AUTOSAR XML (schema 4-0-1)
standard types defined: Boolean, Double, Double_dataConstr, Double_with_NaN, Float, Float_dataConstr, Float_with_NaN, SInt16, SInt16_dataConstr, SInt32, SInt32_dataConstr, SInt8, SInt8_dataConstr, UInt16, UInt16_dataConstr, UInt32, UInt32_dataConstr, UInt8, UInt8_dataConstr, float32, float64, sint16, sint32, sint8, uint16, uint32, uint8, boolean
package /AUTOSAR/DataTypes
  impl type ACC_ACCEPBrequest_datatype: compu {identical}, implementation-data-type=boolean
  impl type ACC_ACCMode_datatype: compu {identical}, range raw 0..255, implementation-data-type=uint8
  impl type ACC_ACCTargetAcceleration_datatype: compu {texttable; unit m/s2}, range raw 0..255, implementation-data-type=uint8
  impl type ACC_ACCTargetDirection_datatype: compu {identical}, range raw 0..255, implementation-data-type=uint8
  impl type ACC_ACCTargetID_datatype: compu {texttable}, range raw 0..255, implementation-data-type=uint8
  impl type ACC_ACCTargetLatRange_datatype: compu {texttable; unit m}, range raw 0..65535, implementation-data-type=uint16
  impl type ACC_ACCTargetLngRange_datatype: compu {texttable; unit m}, range raw 0..65535, implementation-data-type=uint16
  impl type ACC_ACCTargetRelSpd_datatype: compu {texttable; unit km/h}, range raw 0..65535, implementation-data-type=uint16
  impl type ACC_ACCTargetType_datatype: compu {identical}, range raw 0..255, implementation-data-type=uint8
  impl type ACC_AWBlevel_datatype: compu {identical}, range raw 0..255, implementation-data-type=uint8
  impl type ACC_AccTrqReqActive_datatype: compu {identical}, implementation-data-type=boolean
  impl type ACC_AccTrqReq_datatype: compu {texttable; unit Nm}, range raw 0..65535, implementation-data-type=uint16
  impl type ACC_CDDActive_datatype: compu {identical}, implementation-data-type=boolean
  impl type ACC_CRCCheck_1BA_0_datatype: compu {texttable}, range raw 0..255, implementation-data-type=uint8
  impl type ACC_CRCCheck_1BA_1_datatype: compu {texttable}, range raw 0..255, implementation-data-type=uint8
  impl type ACC_CRCCheck_24E_datatype: compu {texttable}, range raw 0..255, implementation-data-type=uint8
  impl type ACC_CRCCheck_25E_datatype: compu {texttable}, range raw 0..255, implementation-data-type=uint8
  impl type ACC_CRCCheck_307_datatype: compu {texttable}, range raw 0..65535, implementation-data-type=uint16
  impl type ACC_CRCCheck_30A_datatype: compu {texttable}, range raw 0..255, implementation-data-type=uint8
  impl type ACC_CRCCheck_30D_datatype: compu {texttable}, range raw 0..255, implementation-data-type=uint8
  impl type ACC_CRCCheck_31A_datatype: compu {texttable}, range raw 0..65535, implementation-data-type=uint16
  impl type ACC_CRCCheck_322_datatype: compu {texttable}, range raw 0..255, implementation-data-type=uint8
  impl type ACC_CRCCheck_344_datatype: compu {texttable}, range raw 0..255, implementation-data-type=uint8
  impl type ACC_CRCCheck_35E_datatype: compu {texttable}, range raw 0..255, implementation-data-type=uint8
  impl type ACC_CRCCheck_35F_datatype: compu {texttable}, range raw 0..255, implementation-data-type=uint8
  impl type ACC_CRCCheck_367_datatype: compu {texttable}, range raw 0..255, implementation-data-type=uint8
  impl type ACC_CRCCheck_36D_datatype: compu {texttable}, range raw 0..255, implementation-data-type=uint8
  impl type ACC_CRCCheck_3E4_datatype: compu {texttable}, range raw 0..255, implementation-data-type=uint8
  impl type ACC_DecToStop_datatype: compu {identical}, implementation-data-type=boolean
  impl type ACC_DistanceLevel_datatype: compu {identical}, range raw 0..255, implementation-data-type=uint8
  impl type ACC_Driveoff_Request_datatype: compu {identical}, implementation-data-type=boolean
  impl type ACC_DriverHandsOffStatus_datatype: compu {identical}, range raw 0..255, implementation-data-type=uint8
  impl type ACC_EmergencyLightingRequest_datatype: compu {identical}, range raw 0..255, implementation-data-type=uint8
  impl type ACC_HandsOnReq_datatype: compu {identical}, range raw 0..255, implementation-data-type=uint8
  impl type ACC_HostLaneLeftStatus_datatype: compu {identical}, range raw 0..255, implementation-data-type=uint8
  impl type ACC_HostLaneRightStatus_datatype: compu {identical}, range raw 0..255, implementation-data-type=uint8
  impl type ACC_IACCHWAMode_datatype: compu {identical}, range raw 0..255, implementation-data-type=uint8
  impl type ACC_IACCHWATextInfoForDriver_datatype: compu {identical}, range raw 0..255, implementation-data-type=uint8
  impl type ACC_LLaneDistanceFusion_datatype: compu {texttable; unit m}, range raw 0..255, implementation-data-type=uint8
  impl type ACC_LatAngReqActive_datatype: compu {identical}, implementation-data-type=boolean
  impl type ACC_LatAngReq_datatype: compu {texttable; unit degree}, range raw 0..65535, implementation-data-type=uint16
  impl type ACC_LatTakeoverReq_datatype: compu {identical}, range raw 0..255, implementation-data-type=uint8
  impl type ACC_LngTakeOverReq_datatype: compu {identical}, range raw 0..255, implementation-data-type=uint8
  impl type ACC_MotorTorqueMaxLimitRequest_datatype: compu {texttable; unit Nm}, range raw 0..65535, implementation-data-type=uint16
  impl type ACC_MotorTorqueMinLimitRequest_datatype: compu {texttable; unit Nm}, range raw 0..65535, implementation-data-type=uint16
  impl type ACC_ObjValid_datatype: compu {identical}, implementation-data-type=boolean
  impl type ACC_RLaneDistanceFusion_datatype: compu {texttable; unit m}, range raw 0..255, implementation-data-type=uint8
  impl type ACC_RollingCounter_1BA_0_datatype: compu {texttable}, range raw 0..255, implementation-data-type=uint8
  impl type ACC_RollingCounter_1BA_1_datatype: compu {texttable}, range raw 0..255, implementation-data-type=uint8
  impl type ACC_RollingCounter_24E_datatype: compu {texttable}, range raw 0..255, implementation-data-type=uint8
  impl type ACC_RollingCounter_25E_datatype: compu {texttable}, range raw 0..255, implementation-data-type=uint8
  impl type ACC_RollingCounter_307_datatype: compu {texttable}, range raw 0..255, implementation-data-type=uint8
  impl type ACC_RollingCounter_30A_datatype: compu {texttable}, range raw 0..255, implementation-data-type=uint8
  impl type ACC_RollingCounter_30D_datatype: compu {texttable}, range raw 0..255, implementation-data-type=uint8
  impl type ACC_RollingCounter_31A_datatype: compu {texttable}, range raw 0..255, implementation-data-type=uint8
  impl type ACC_RollingCounter_322_datatype: compu {texttable}, range raw 0..255, implementation-data-type=uint8
  impl type ACC_RollingCounter_344_datatype: compu {texttable}, range raw 0..255, implementation-data-type=uint8
  impl type ACC_RollingCounter_35E_datatype: compu {texttable}, range raw 0..255, implementation-data-type=uint8
  impl type ACC_RollingCounter_35F_datatype: compu {texttable}, range raw 0..255, implementation-data-type=uint8
  impl type ACC_RollingCounter_367_datatype: compu {texttable}, range raw 0..255, implementation-data-type=uint8
  impl type ACC_RollingCounter_36D_datatype: compu {texttable}, range raw 0..255, implementation-data-type=uint8
  impl type ACC_RollingCounter_3E4_datatype: compu {texttable}, range raw 0..255, implementation-data-type=uint8
  impl type ACC_SaftyBeltVibrationReq_datatype: compu {identical}, implementation-data-type=boolean
  impl type ACC_SaftyBelt_Tightened_datatype: compu {identical}, range raw 0..255, implementation-data-type=uint8
  impl type ACC_SetSpeed_datatype: compu {texttable; unit Km/h}, range raw 0..255, implementation-data-type=uint8
  impl type ACC_TargetBasedLateralControl_datatype: compu {identical}, range raw 0..255, implementation-data-type=uint8
  impl type ACC_TextInfoForDriver_datatype: compu {identical}, range raw 0..255, implementation-data-type=uint8
  impl type ACC_TimeGapSet_datatype: compu {identical}, range raw 0..255, implementation-data-type=uint8
  impl type ACC_Voiceinfo_datatype: compu {identical}, range raw 0..255, implementation-data-type=uint8
  impl type ADS_Authernticator_1BA_datatype: category=ARRAY, compu {texttable}
    element ADS_Authernticator_1BA_datatype: array-size=8, array-size-semantics=FIXED-SIZE, implementation-data-type=uint8
  impl type ADS_Authernticator_244_datatype: category=ARRAY, compu {texttable}
    element ADS_Authernticator_244_datatype: array-size=8, array-size-semantics=FIXED-SIZE, implementation-data-type=uint8
  impl type ADS_CRCCheck_244_datatype: compu {texttable}, range raw 0..65535, implementation-data-type=uint16
  impl type ADS_CRCCheck_312_datatype: compu {texttable}, range raw 0..65535, implementation-data-type=uint16
  impl type ADS_MesssageCounter_1BA_datatype: compu {texttable}, range raw 0..255, implementation-data-type=uint8
  impl type ADS_MesssageCounter_244_datatype: compu {texttable}, range raw 0..255, implementation-data-type=uint8
  impl type ADS_ResetFlag_1BA_datatype: compu {texttable}, range raw 0..255, implementation-data-type=uint8
  impl type ADS_ResetFlag_244_datatype: compu {texttable}, range raw 0..255, implementation-data-type=uint8
  impl type ADS_RollingCounter_244_datatype: compu {texttable}, range raw 0..255, implementation-data-type=uint8
  impl type ADS_RollingCounter_312_datatype: compu {texttable}, range raw 0..255, implementation-data-type=uint8
  impl type BCM_CRCCheck_28B_datatype: compu {texttable}, range raw 0..255, implementation-data-type=uint8
  impl type BCM_RollingCounter_28B_datatype: compu {texttable}, range raw 0..255, implementation-data-type=uint8
  impl type BCM_TurnLightSwitchSts_datatype: compu {identical}, range raw 0..255, implementation-data-type=uint8
  impl type BcmAutHeadLiSts_datatype: compu {identical}, implementation-data-type=boolean
  impl type BcmCrcChk288_datatype: compu {texttable}, range raw 0..255, implementation-data-type=uint8
  impl type BcmCycCntr288_datatype: compu {texttable}, range raw 0..255, implementation-data-type=uint8
  impl type BcmDrvrDoorSts_datatype: compu {identical}, implementation-data-type=boolean
  impl type BcmFrntFogLmpSts_datatype: compu {identical}, range raw 0..255, implementation-data-type=uint8
  impl type BcmFrntWiperSts_datatype: compu {identical}, range raw 0..255, implementation-data-type=uint8
  impl type BcmHiBeamSts_datatype: compu {identical}, range raw 0..255, implementation-data-type=uint8
  4 x impl type, all with category=TYPE_REFERENCE, compu {identical}:
    BcmHoodSts_datatype: implementation-data-type=boolean
    BcmLeReDoorSts_datatype: implementation-data-type=boolean
    BcmLiSnsrFlt_datatype: implementation-data-type=boolean
    BcmLoBeamSts_datatype: range raw 0..255, implementation-data-type=uint8
  impl type BcmPassDoorSts_datatype: compu {identical}, implementation-data-type=boolean
  impl type BcmReFoglmpSts_datatype: compu {identical}, range raw 0..255, implementation-data-type=uint8
  impl type BcmRiReDoorSts_datatype: compu {identical}, implementation-data-type=boolean
  impl type BcmStsRainSnsr_datatype: compu {identical}, implementation-data-type=boolean
  impl type BcmTurnIndcrLe_datatype: compu {identical}, range raw 0..255, implementation-data-type=uint8
  impl type BcmTurnIndcrRi_datatype: compu {identical}, range raw 0..255, implementation-data-type=uint8
  impl type CdcCycChk2D2_datatype: compu {texttable}, range raw 0..65535, implementation-data-type=uint16
  impl type CdcCycCntr2D2_datatype: compu {texttable}, range raw 0..255, implementation-data-type=uint8
  impl type CdcTotMilg_datatype: compu {texttable; unit Km}, range raw 0..4294967295, implementation-data-type=uint32
  impl type Char16: implementation-data-type=uint8
  impl type Char8: implementation-data-type=uint8
  range Double_with_NaN_dataConstr: raw -INF..INF
  impl type EPB_APArequest_Available_datatype: compu {identical}, implementation-data-type=boolean
  impl type EPB_AchievedClampForce_Primary_datatype: compu {texttable; unit KN}, range raw 0..255, implementation-data-type=uint8
  impl type EPB_AchievedClampForce_datatype: compu {texttable; unit KN}, range raw 0..255, implementation-data-type=uint8
  impl type EPB_FailStatuss_Primary_datatype: compu {identical}, range raw 0..255, implementation-data-type=uint8
  impl type EPS_ADASActiveMode_datatype: compu {identical}, range raw 0..255, implementation-data-type=uint8
  impl type EPS_ADS_Abortfeedback_datatype: compu {identical}, range raw 0..255, implementation-data-type=uint8
  impl type EPS_ADS_ControlFeedback_datatype: compu {identical}, range raw 0..255, implementation-data-type=uint8
  impl type EPS_ActualMotorTorq_datatype: compu {texttable; unit Nm}, range raw 0..65535, implementation-data-type=uint16
  impl type EPS_ActualTorsionBarTorq_datatype: compu {texttable; unit Nm}, range raw 0..65535, implementation-data-type=uint16
  impl type EPS_CRCCheck_170_datatype: compu {texttable}, range raw 0..255, implementation-data-type=uint8
  impl type EPS_CRCCheck_17E_datatype: compu {texttable}, range raw 0..255, implementation-data-type=uint8
  impl type EPS_CRCCheck_24F_datatype: compu {texttable}, range raw 0..255, implementation-data-type=uint8
  impl type EPS_ConcussAvailabilityStatus_datatype: compu {identical}, range raw 0..255, implementation-data-type=uint8
  impl type EPS_Handwheel_Relang_Valid_datatype: compu {identical}, implementation-data-type=boolean
  impl type EPS_Handwheel_Relang_datatype: compu {texttable; unit degree}, range raw 0..65535, implementation-data-type=uint16
  impl type EPS_IACC_abortreason_datatype: compu {identical}, range raw 0..255, implementation-data-type=uint8
  impl type EPS_LDW_ShakeLevStatus_datatype: compu {identical}, range raw 0..255, implementation-data-type=uint8
  impl type EPS_LatCtrlActive_datatype: compu {identical}, implementation-data-type=boolean
  impl type EPS_LatCtrlAvailabilityStatus_datatype: compu {identical}, range raw 0..255, implementation-data-type=uint8
  impl type EPS_MaxSafetyTorsionBarTorq_datatype: compu {texttable; unit Nm}, range raw 0..65535, implementation-data-type=uint16
  impl type EPS_MeasuredTorsionBarTorqValid_datatype: compu {identical}, implementation-data-type=boolean
  impl type EPS_MeasuredTorsionBarTorque_datatype: compu {texttable; unit Nm}, range raw 0..65535, implementation-data-type=uint16
  impl type EPS_MinSafetyTorsionBarTorq_datatype: compu {texttable; unit Nm}, range raw 0..65535, implementation-data-type=uint16
  impl type EPS_Pinionang_Valid_datatype: compu {identical}, implementation-data-type=boolean
  impl type EPS_Pinionang_datatype: compu {texttable; unit degree}, range raw 0..65535, implementation-data-type=uint16
  impl type EPS_RollingCounter_170_datatype: compu {texttable}, range raw 0..255, implementation-data-type=uint8
  impl type EPS_RollingCounter_17E_datatype: compu {texttable}, range raw 0..255, implementation-data-type=uint8
  impl type EPS_RollingCounter_24F_datatype: compu {texttable}, range raw 0..255, implementation-data-type=uint8
  impl type EPS_SteeringTorque_datatype: compu {texttable; unit Nm}, range raw 0..255, implementation-data-type=uint8
  impl type EPS_SystemSt_datatype: compu {identical}, range raw 0..255, implementation-data-type=uint8
  6 x impl type, all with category=TYPE_REFERENCE, compu {identical}:
    EPS_TorqSensorStatus_datatype: implementation-data-type=boolean
    ESP_ABAactive_datatype: implementation-data-type=boolean
    ESP_ABAavailable_datatype: implementation-data-type=boolean
    ESP_AEBAvailable_datatype: implementation-data-type=boolean
    ESP_AEBdecActive_datatype: implementation-data-type=boolean
    ESP_APAFailureSts_datatype: range raw 0..255, implementation-data-type=uint8
  impl type ESP_APAStatus_datatype: compu {identical}, range raw 0..255, implementation-data-type=uint8
  10 x impl type, all with category=TYPE_REFERENCE:
    ESP_APA_CDDAPVehicleHold_datatype: compu {identical}, implementation-data-type=boolean
    ESP_APA_DriverOverride_datatype: compu {identical}, implementation-data-type=boolean
    ESP_AWBactive_datatype: compu {identical}, implementation-data-type=boolean
    ESP_AWBavailable_datatype: compu {identical}, implementation-data-type=boolean
    ESP_Available_ReducedFunction_datatype: compu {identical}, implementation-data-type=boolean
    ESP_BrakeForce_datatype: compu {identical}, implementation-data-type=boolean
    ESP_BrakeOverHeatBrakeDiscTemp_datatype: compu {identical}, implementation-data-type=boolean
    ESP_CDD_Active_datatype: compu {identical}, implementation-data-type=boolean
    ESP_CDD_Available_datatype: compu {identical}, implementation-data-type=boolean
    ESP_CRCCheck_17A_datatype: compu {texttable}, range raw 0..65535, implementation-data-type=uint16
  5 x impl type, all with category=TYPE_REFERENCE, compu {identical}:
    ESP_PrefillActive_datatype: implementation-data-type=boolean
    ESP_PrefillAvailable_datatype: implementation-data-type=boolean
    ESP_PrefillforAPA_Available_datatype: implementation-data-type=boolean
    ESP_PrefillforAPA_active_datatype: implementation-data-type=boolean
    ESP_QDCACC_datatype: range raw 0..255, implementation-data-type=uint8
  impl type ESP_RollingCounter_17A_datatype: compu {texttable}, range raw 0..255, implementation-data-type=uint8
  impl type ESP_UrgencyBrakeAlarm_datatype: compu {identical}, implementation-data-type=boolean
  impl type ESP__Available_FullFunction_datatype: compu {identical}, range raw 0..255, implementation-data-type=uint8
  impl type EpbFailrSts_datatype: compu {identical}, range raw 0..255, implementation-data-type=uint8
  impl type EpbStsPrimary_datatype: compu {identical}, range raw 0..255, implementation-data-type=uint8
  impl type EpbSts_datatype: compu {identical}, range raw 0..255, implementation-data-type=uint8
  impl type EpsFaild_datatype: compu {identical}, range raw 0..255, implementation-data-type=uint8
  impl type EpsSasCalSts_datatype: compu {identical}, implementation-data-type=boolean
  impl type EpsSasSteerAgVld_datatype: compu {identical}, implementation-data-type=boolean
  impl type EpsSasSteerAg_datatype: compu {texttable; unit degree}, range raw -32768..32767, implementation-data-type=sint16
  impl type EpsSteerAgRate_datatype: compu {texttable; unit deg/s}, range raw 0..255, implementation-data-type=uint8
  impl type EpsSteerAgSensFilr_datatype: compu {identical}, implementation-data-type=boolean
  impl type EpsSteerModFb_datatype: compu {identical}, range raw 0..255, implementation-data-type=uint8
  4 x impl type, all with category=TYPE_REFERENCE, compu {identical}:
    EspAbsActv_datatype: implementation-data-type=boolean
    EspAbsFailr_datatype: implementation-data-type=boolean
    EspActvSts_datatype: implementation-data-type=boolean
    EspAutoHoldActvSts_datatype: range raw 0..255, implementation-data-type=uint8
  impl type EspBrkLiOnReq_datatype: compu {identical}, range raw 0..255, implementation-data-type=uint8
  impl type EspCrcChk1C2_datatype: compu {texttable}, range raw 0..65535, implementation-data-type=uint16
  impl type EspCrcChk3C2_datatype: compu {texttable}, range raw 0..65535, implementation-data-type=uint16
  impl type EspCycCntr1C2_datatype: compu {texttable}, range raw 0..255, implementation-data-type=uint8
  impl type EspCycCntr3C2_datatype: compu {texttable}, range raw 0..255, implementation-data-type=uint8
  5 x impl type, all with category=TYPE_REFERENCE:
    EspEbdFailr_datatype: compu {identical}, implementation-data-type=boolean
    EspEpbReqAvl_datatype: compu {identical}, implementation-data-type=boolean
    EspFctOpenSts_datatype: compu {identical}, implementation-data-type=boolean
    EspReWhlDecTarTqActv_datatype: compu {identical}, implementation-data-type=boolean
    EspReWhlDecTarTq_datatype: compu {texttable; unit Nm}, range raw 0..65535, implementation-data-type=uint16
  impl type EspReWhlIncTarTqActv_datatype: compu {identical}, implementation-data-type=boolean
  impl type EspReWhlIncTarTq_datatype: compu {texttable; unit Nm}, range raw 0..65535, implementation-data-type=uint16
  impl type EspTcsFailr_datatype: compu {identical}, implementation-data-type=boolean
  impl type EspVehSpdVld_datatype: compu {identical}, implementation-data-type=boolean
  impl type EspVehSpd_datatype: compu {texttable; unit km/h}, range raw 0..65535, implementation-data-type=uint16
  impl type EspVehStandstill_datatype: compu {identical}, implementation-data-type=boolean
  range Float_with_NaN_dataConstr: raw -INF..INF
  impl type GW_Authernticator_1AD_datatype: compu {texttable}, range raw 0..65535, implementation-data-type=uint16
  impl type GW_ResetCounter_1AD_datatype: compu {texttable}, range raw 0..4294967295, implementation-data-type=uint32
  impl type GW_TripCounter_1AD_datatype: compu {texttable}, range raw 0..4294967295, implementation-data-type=uint32
  impl type HU_AutoBrakeEnable_datatype: compu {identical}, implementation-data-type=boolean
  impl type HU_ELKEnable_datatype: compu {identical}, range raw 0..255, implementation-data-type=uint8
  impl type HU_FCWSetting_datatype: compu {identical}, range raw 0..255, implementation-data-type=uint8
  impl type HU_HMAEnable_datatype: compu {identical}, implementation-data-type=boolean
  impl type HU_IACCEnable_datatype: compu {identical}, range raw 0..255, implementation-data-type=uint8
  impl type HU_LASModeSelection_datatype: compu {identical}, range raw 0..255, implementation-data-type=uint8
  impl type HU_LASWarningModeSelection_datatype: compu {identical}, range raw 0..255, implementation-data-type=uint8
  impl type HU_VC_CruiseControl_datatype: compu {identical}, range raw 0..255, implementation-data-type=uint8
  impl type HU_VC_CruiseSetDistance_datatype: compu {identical}, range raw 0..255, implementation-data-type=uint8
  impl type HU_VC_CruiseSetSpeed_datatype: compu {identical}, range raw 0..255, implementation-data-type=uint8
  impl type IBBrkPedlModSts_datatype: compu {identical}, range raw 0..255, implementation-data-type=uint8
  impl type IBBrkPedlModSwtAvl_datatype: compu {identical}, implementation-data-type=boolean
  impl type IBCU_BrakeDiscHighTempWarning_datatype: compu {identical}, range raw 0..255, implementation-data-type=uint8
  impl type IBCU_CDDAvailableStatus_datatype: compu {identical}, range raw 0..255, implementation-data-type=uint8
  impl type IBCU_PFSBrakePressureValid_datatype: compu {identical}, implementation-data-type=boolean
  impl type IBCU_PFSBrakePressure_datatype: compu {texttable; unit bar}, range raw 0..65535, implementation-data-type=uint16
  impl type IBCU_PlungerBrakePressureValid_datatype: compu {identical}, implementation-data-type=boolean
  impl type IBCU_PlungerBrakePressure_datatype: compu {texttable; unit bar}, range raw 0..65535, implementation-data-type=uint16
  impl type IP_CRCCheck_2DE_datatype: compu {texttable}, range raw 0..255, implementation-data-type=uint8
  impl type IP_DISFail_datatype: compu {identical}, implementation-data-type=boolean
  impl type IP_QDashACCFail_datatype: compu {identical}, range raw 0..255, implementation-data-type=uint8
  impl type IP_RollingCounter_2DE_datatype: compu {texttable}, range raw 0..255, implementation-data-type=uint8
  impl type IbBrkPedlStsGbVld_datatype: compu {identical}, range raw 0..255, implementation-data-type=uint8
  impl type IbBrkPedlStsGb_datatype: compu {identical; unit %}, range raw 0..255, implementation-data-type=uint8
  impl type IbCrcChk2C2_datatype: compu {texttable}, range raw 0..65535, implementation-data-type=uint16
  impl type IbCycCntr2C2_datatype: compu {texttable}, range raw 0..255, implementation-data-type=uint8
  impl type LAS_DTC1_HighByte_datatype: compu {texttable}, range raw 0..255, implementation-data-type=uint8
  impl type LAS_DTC1_LowByte_datatype: compu {texttable}, range raw 0..255, implementation-data-type=uint8
  impl type LAS_DTC1_MiddByte_datatype: compu {texttable}, range raw 0..255, implementation-data-type=uint8
  impl type LAS_DTC1_Status_datatype: compu {texttable}, range raw 0..255, implementation-data-type=uint8
  impl type LAS_DTC2_HighByte_datatype: compu {texttable}, range raw 0..255, implementation-data-type=uint8
  impl type LAS_DTC2_LowByte_datatype: compu {texttable}, range raw 0..255, implementation-data-type=uint8
  impl type LAS_DTC2_MiddByte_datatype: compu {texttable}, range raw 0..255, implementation-data-type=uint8
  impl type LAS_DTC2_Status_datatype: compu {texttable}, range raw 0..255, implementation-data-type=uint8
  impl type LCDAR_CRCCheck_2AF_datatype: compu {texttable}, range raw 0..255, implementation-data-type=uint8
  impl type LCDAR_ELK_oAlert_datatype: compu {identical}, range raw 0..255, implementation-data-type=uint8
  impl type LCDAR_ELK_oStatus_datatype: compu {identical}, range raw 0..255, implementation-data-type=uint8
  impl type LCDAR_Left_ELK_oAlert_datatype: compu {identical}, range raw 0..255, implementation-data-type=uint8
  impl type LCDAR_Left_RCTAAlert_datatype: compu {identical}, range raw 0..255, implementation-data-type=uint8
  impl type LCDAR_RCTBActive_datatype: compu {identical}, implementation-data-type=boolean
  impl type LCDAR_RCTBEnable_datatype: compu {identical}, implementation-data-type=boolean
  impl type LCDAR_RCTBTargetDecel_datatype: compu {texttable; unit m/s2}, range raw 0..65535, implementation-data-type=uint16
  impl type LCDAR_RollingCounter_2AF_datatype: compu {texttable}, range raw 0..255, implementation-data-type=uint8
  impl type MbRgnTarWhlQlfr_datatype: compu {identical}, range raw 0..255, implementation-data-type=uint8
  impl type MbRgnTarWhl_datatype: compu {texttable; unit Nm}, range raw 0..65535, implementation-data-type=uint16
  4 x impl type, all with category=TYPE_REFERENCE:
    RBM_CDD_Active_APA_datatype: compu {identical}, implementation-data-type=boolean
    RBM_CDD_Available_APA_datatype: compu {identical}, implementation-data-type=boolean
    RBM_FailStatus_datatype: compu {identical}, implementation-data-type=boolean
    RbmCrcChk22B_datatype: compu {texttable}, range raw 0..65535, implementation-data-type=uint16
  impl type RbmCycCntr22B_datatype: compu {texttable}, range raw 0..255, implementation-data-type=uint8
  impl type RbmEPBCoordination_Secondary_datatype: compu {texttable}, range raw 0..65535, implementation-data-type=uint16
  impl type RbmEPBSafetyLimiterState_Seconda_datatype: compu {texttable}, implementation-data-type=boolean
  impl type RbmEPB_AchievedClampForce_Second_datatype: compu {texttable; unit KN}, range raw 0..255, implementation-data-type=uint8
  impl type RbmEPB_FailStatuss_Secondary_datatype: compu {identical}, range raw 0..255, implementation-data-type=uint8
  11 x impl type, all with category=TYPE_REFERENCE, compu {identical}:
    RbmESP_ABAactive_datatype: implementation-data-type=boolean
    RbmESP_ABAavailable_datatype: implementation-data-type=boolean
    RbmESP_AEBAvailable_datatype: implementation-data-type=boolean
    RbmESP_AEBdecActive_datatype: implementation-data-type=boolean
    RbmESP_AWBactive_datatype: implementation-data-type=boolean
    RbmESP_AWBavailable_datatype: implementation-data-type=boolean
    RbmESP_CDD_Active_datatype: implementation-data-type=boolean
    RbmESP_CDD_Available_datatype: implementation-data-type=boolean
    RbmESP_PrefillActive_datatype: implementation-data-type=boolean
    RbmESP_PrefillAvailable_datatype: implementation-data-type=boolean
    RbmESP_QDCACC_datatype: range raw 0..255, implementation-data-type=uint8
  impl type RbmEpbFailrLamp_Secondary_datatype: compu {identical}, range raw 0..255, implementation-data-type=uint8
  impl type RbmEpbFctLamp_Secondary_datatype: compu {identical}, range raw 0..255, implementation-data-type=uint8
  impl type RbmEpbStsSecondary_datatype: compu {identical}, range raw 0..255, implementation-data-type=uint8
  impl type RbmEpbTextDispReq_Secondary_datatype: compu {identical}, range raw 0..255, implementation-data-type=uint8
  impl type RbmEspAbsFailr_datatype: compu {identical}, implementation-data-type=boolean
  impl type RbmEspVehSpdVld_datatype: compu {identical}, implementation-data-type=boolean
  impl type RbmRbmEspVehSpd_datatype: compu {texttable; unit km/h}, range raw 0..65535, implementation-data-type=uint16
  impl type RbmWheel_Speed_FL_Data_datatype: compu {texttable; unit km/h}, range raw 0..65535, implementation-data-type=uint16
  impl type RbmWheel_Speed_FL_Direction_datatype: compu {identical}, range raw 0..255, implementation-data-type=uint8
  impl type RbmWheel_Speed_FL_Pulse_datatype: compu {texttable}, range raw 0..255, implementation-data-type=uint8
  impl type RbmWheel_Speed_FL_Valid_Data_datatype: compu {identical}, implementation-data-type=boolean
  impl type RbmWheel_Speed_FR_Data_datatype: compu {texttable; unit km/h}, range raw 0..65535, implementation-data-type=uint16
  impl type RbmWheel_Speed_FR_Direction_datatype: compu {identical}, range raw 0..255, implementation-data-type=uint8
  impl type RbmWheel_Speed_FR_Pulse_datatype: compu {texttable}, range raw 0..255, implementation-data-type=uint8
  impl type RbmWheel_Speed_FR_Valid_Data_datatype: compu {identical}, implementation-data-type=boolean
  impl type RbmWheel_Speed_RL_Data_datatype: compu {texttable; unit km/h}, range raw 0..65535, implementation-data-type=uint16
  impl type RbmWheel_Speed_RL_Direction_datatype: compu {identical}, range raw 0..255, implementation-data-type=uint8
  impl type RbmWheel_Speed_RL_Pulse_datatype: compu {texttable}, range raw 0..255, implementation-data-type=uint8
  impl type RbmWheel_Speed_RL_Valid_Data_datatype: compu {identical}, implementation-data-type=boolean
  impl type RbmWheel_Speed_RR_Data_datatype: compu {texttable; unit km/h}, range raw 0..65535, implementation-data-type=uint16
  impl type RbmWheel_Speed_RR_Direction_datatype: compu {identical}, range raw 0..255, implementation-data-type=uint8
  impl type RbmWheel_Speed_RR_Pulse_datatype: compu {texttable}, range raw 0..255, implementation-data-type=uint8
  impl type RbmWheel_Speed_RR_Valid_Data_datatype: compu {identical}, implementation-data-type=boolean
  impl type SInt4: range raw -8..7, implementation-data-type=sint8
  impl type SrsCrashOutpStsChks_datatype: compu {identical}, range raw 0..255, implementation-data-type=uint8
  impl type SrsCrashOutpSts_datatype: compu {identical}, range raw 0..255, implementation-data-type=uint8
  impl type SrsCrcChk050_datatype: compu {texttable}, range raw 0..255, implementation-data-type=uint8
  impl type SrsCycCntr050_datatype: compu {texttable}, range raw 0..255, implementation-data-type=uint8
  impl type SrsDrvrBucSwtSts_datatype: compu {identical}, range raw 0..255, implementation-data-type=uint8
  impl type SrsPassBucSwtSts_datatype: compu {identical}, range raw 0..255, implementation-data-type=uint8
  impl type SrsWarnLampSts_datatype: compu {identical}, range raw 0..255, implementation-data-type=uint8
  impl type TboxLocalTiDate_datatype: compu {texttable; unit day}, range raw 0..255, implementation-data-type=uint8
  impl type TboxLocalTiHr_datatype: compu {texttable; unit hour}, range raw 0..255, implementation-data-type=uint8
  impl type TboxLocalTiMins_datatype: compu {texttable; unit minute}, range raw 0..255, implementation-data-type=uint8
  impl type TboxLocalTiMth_datatype: compu {texttable; unit month}, range raw 0..255, implementation-data-type=uint8
  impl type TboxLocalTiSec_datatype: compu {texttable; unit second}, range raw 0..255, implementation-data-type=uint8
  impl type TboxLocalTiVld_datatype: compu {identical}, implementation-data-type=boolean
  impl type TboxLocalTiYear_datatype: compu {texttable; unit year}, range raw 0..255, implementation-data-type=uint8
  impl type TmsAcEnvtlTVld_datatype: compu {identical}, implementation-data-type=boolean
  impl type TmsAcEnvtlT_datatype: compu {texttable; unit ��}, range raw 0..255, implementation-data-type=uint8
  impl type TmsActPwr_datatype: compu {texttable; unit kW}, range raw 0..65535, implementation-data-type=uint16
  impl type TmsFrntBlowMod_datatype: compu {identical}, range raw 0..255, implementation-data-type=uint8
  impl type UInt4: range raw 0..15, implementation-data-type=uint8
  impl type UInt8_n: category=ARRAY
    element UInt8_n: array-size=8, array-size-semantics=FIXED-SIZE, implementation-data-type=uint8
  impl type VCUAPARequestEnable_datatype: compu {identical}, range raw 0..255, implementation-data-type=uint8
  impl type VCUAPAdriverInterruption_datatype: compu {identical}, range raw 0..255, implementation-data-type=uint8
  4 x impl type, all with category=TYPE_REFERENCE, compu {identical}:
    VCUAccPedShield_datatype: implementation-data-type=boolean
    VCUShiftPostionValid_datatype: implementation-data-type=boolean
    VcuAPATorqRequestAvailable_datatype: implementation-data-type=boolean
    VcuAccrMod_datatype: range raw 0..255, implementation-data-type=uint8
  impl type VcuAccrPedlPosnVld_datatype: compu {identical}, implementation-data-type=boolean
  impl type VcuAccrPedlPosn_datatype: compu {texttable; unit %}, range raw 0..65535, implementation-data-type=uint16
  impl type VcuCRCCheck_38A_datatype: compu {texttable}, range raw 0..255, implementation-data-type=uint8
  impl type VcuCalcnAccrPedlPosnVld_datatype: compu {identical}, implementation-data-type=boolean
  impl type VcuCalcnAccrPedlPosn_datatype: compu {texttable; unit %}, range raw 0..65535, implementation-data-type=uint16
  impl type VcuComFltSts_datatype: compu {identical}, range raw 0..255, implementation-data-type=uint8
  impl type VcuCrcChk161_datatype: compu {texttable}, range raw 0..65535, implementation-data-type=uint16
  impl type VcuCrsDstSwtPlusSts_datatype: compu {identical}, range raw 0..255, implementation-data-type=uint8
  impl type VcuCrsDstSwtReduceSts_datatype: compu {identical}, range raw 0..255, implementation-data-type=uint8
  impl type VcuCrsResuSwtSts_datatype: compu {identical}, range raw 0..255, implementation-data-type=uint8
  impl type VcuCrsSetSwtSts_datatype: compu {identical}, range raw 0..255, implementation-data-type=uint8
  impl type VcuCrsSwtDiagInfo_datatype: compu {identical}, range raw 0..255, implementation-data-type=uint8
  impl type VcuCycCntr161_datatype: compu {texttable}, range raw 0..255, implementation-data-type=uint8
  impl type VcuEnyRecyclMod_datatype: compu {identical}, range raw 0..255, implementation-data-type=uint8
  impl type VcuGearPosn_datatype: compu {identical}, range raw 0..255, implementation-data-type=uint8
  impl type VcuOvrdModReq_datatype: compu {identical}, implementation-data-type=boolean
  impl type VcuPtTqLimMaxVld_datatype: compu {identical}, implementation-data-type=boolean
  impl type VcuPtTqLimMax_datatype: compu {texttable; unit Nm}, range raw 0..65535, implementation-data-type=uint16
  impl type VcuPtTqLimMinVld_datatype: compu {identical}, implementation-data-type=boolean
  impl type VcuPtTqLimMin_datatype: compu {texttable; unit Nm}, range raw 0..65535, implementation-data-type=uint16
  impl type VcuPtTqRealVld_datatype: compu {identical}, implementation-data-type=boolean
  impl type VcuPtTqReal_datatype: compu {texttable; unit Nm}, range raw 0..65535, implementation-data-type=uint16
  impl type VcuPtTqReqAvl_datatype: compu {identical}, range raw 0..255, implementation-data-type=uint8
  impl type VcuRdySts_datatype: compu {identical}, implementation-data-type=boolean
  impl type VcuRollingCounter_38A_datatype: compu {texttable}, range raw 0..255, implementation-data-type=uint8
  impl type VcuShiftLvlPosn_datatype: compu {identical}, range raw 0..255, implementation-data-type=uint8
  impl type VcuVehGearPosnVld_datatype: compu {identical}, implementation-data-type=boolean
  impl type VcuVehWhlReqTqVld_datatype: compu {identical}, implementation-data-type=boolean
  impl type VcuVehWhlReqTq_datatype: compu {texttable; unit Nm}, range raw 0..65535, implementation-data-type=uint16
  impl type WheelPressureFrontLeft_Model_datatype: compu {texttable; unit bar}, range raw 0..65535, implementation-data-type=uint16
  impl type WheelPressureFrontRight_Model_datatype: compu {texttable; unit bar}, range raw 0..65535, implementation-data-type=uint16
  impl type WheelPressureRearLeft_Model_datatype: compu {texttable; unit bar}, range raw 0..65535, implementation-data-type=uint16
  impl type WheelPressureRearRight_Model_datatype: compu {texttable; unit bar}, range raw 0..65535, implementation-data-type=uint16
  impl type Wheel_SpeedPulseTimeStamp_FL_datatype: compu {texttable; unit ms}, range raw 0..65535, implementation-data-type=uint16
  impl type Wheel_SpeedPulseTimeStamp_FR_datatype: compu {texttable; unit ms}, range raw 0..65535, implementation-data-type=uint16
  impl type WhlSpdFrntLePls_datatype: compu {texttable}, range raw 0..255, implementation-data-type=uint8
  impl type WhlSpdFrntRiPls_datatype: compu {texttable}, range raw 0..255, implementation-data-type=uint8
  impl type WhlSpdLeFrntDataVld_datatype: compu {identical}, implementation-data-type=boolean
  impl type WhlSpdLeFrntData_datatype: compu {texttable; unit km/h}, range raw 0..65535, implementation-data-type=uint16
  impl type WhlSpdLeFrntDir_datatype: compu {identical}, range raw 0..255, implementation-data-type=uint8
  impl type WhlSpdLeReDataVld_datatype: compu {identical}, implementation-data-type=boolean
  impl type WhlSpdLeReData_datatype: compu {texttable; unit km/h}, range raw 0..65535, implementation-data-type=uint16
  impl type WhlSpdLeReDir_datatype: compu {identical}, range raw 0..255, implementation-data-type=uint8
  impl type WhlSpdReLePls_datatype: compu {texttable}, range raw 0..255, implementation-data-type=uint8
  impl type WhlSpdReRiPls_datatype: compu {texttable}, range raw 0..255, implementation-data-type=uint8
  impl type WhlSpdRiFrntDataVld_datatype: compu {identical}, implementation-data-type=boolean
  impl type WhlSpdRiFrntData_datatype: compu {texttable; unit km/h}, range raw 0..65535, implementation-data-type=uint16
  impl type WhlSpdRiFrntDir_datatype: compu {identical}, range raw 0..255, implementation-data-type=uint8
  impl type WhlSpdRiReDataVld_datatype: compu {identical}, implementation-data-type=boolean
  impl type WhlSpdRiReData_datatype: compu {texttable; unit km/h}, range raw 0..65535, implementation-data-type=uint16
  impl type WhlSpdRiReDir_datatype: compu {identical}, range raw 0..255, implementation-data-type=uint8
package /DBCImport
  system CanSystem
  nm config CanSystem_NmConfig: can-nm-cluster-coupling=coupled-cluster=CanNetwork_NmCluster
    can nm cluster CanNetwork_NmCluster: communication-cluster=CanNetwork
      5 x can nm node:
        ADC_NmNode: controller=ADC, nm-if-ecu=ADC_NmEcu
        FC_Public_NmNode: controller=FC_Public, nm-if-ecu=FC_Public_NmEcu
        GW_NmNode: controller=GW, nm-if-ecu=GW_NmEcu
        TBOX_NmNode: controller=TBOX, nm-if-ecu=TBOX_NmEcu
        VCU_NmNode: controller=VCU, nm-if-ecu=VCU_NmEcu
    nm-if-ecus:
      5 x nm ecu:
        ADC_NmEcu: ecu-instance=ADC
        FC_Public_NmEcu: ecu-instance=FC_Public
        GW_NmEcu: ecu-instance=GW
        TBOX_NmEcu: ecu-instance=TBOX
        VCU_NmEcu: ecu-instance=VCU
package /DBCImport/CLUSTERS
  can cluster CanNetwork
    can physical channel CanChannel: comm-connectors=[Conn_ADC, Conn_FC_Public, Conn_GW, Conn_TBOX, Conn_VCU]
      frame ADC_1BA: id 0x1BA, from ADC, to GW, frame-length=32, can-addressing-mode=STANDARD
        pdu ADC_1BA: length=4
          signal ACC_CRCCheck_1BA_0: start 63, 8 bit, big-endian, base-type=uint8, compu {texttable}, implementation-data-type=ACC_CRCCheck_1BA_0_datatype
          signal ACC_CRCCheck_1BA_1: start 127, 8 bit, big-endian, base-type=uint8, compu {texttable}, implementation-data-type=ACC_CRCCheck_1BA_1_datatype, to GW
          signal ACC_LatAngReq: start 17, 14 bit, big-endian, base-type=uint16, compu {texttable; unit degree}, implementation-data-type=ACC_LatAngReq_datatype, to GW
          signal ACC_LatAngReqActive: start 35, 1 bit, big-endian, base-type=uint8, compu {identical}, implementation-data-type=ACC_LatAngReqActive_datatype, to GW
          signal ACC_MotorTorqueMaxLimitRequest: start 7, 11 bit, big-endian, base-type=uint16, compu {texttable; unit Nm}, implementation-data-type=ACC_MotorTorqueMaxLimitRequest_datatype, to GW
          signal ACC_MotorTorqueMinLimitRequest: start 12, 11 bit, big-endian, base-type=uint16, compu {texttable; unit Nm}, implementation-data-type=ACC_MotorTorqueMinLimitRequest_datatype, to GW
          signal ACC_RollingCounter_1BA_0: start 51, 4 bit, big-endian, base-type=uint8, compu {texttable}, implementation-data-type=ACC_RollingCounter_1BA_0_datatype
          signal ACC_RollingCounter_1BA_1: start 115, 4 bit, big-endian, base-type=uint8, compu {texttable}, implementation-data-type=ACC_RollingCounter_1BA_1_datatype, to GW
          signal ADS_Authernticator_1BA: start 207, 56 bit, big-endian, compu {texttable}, implementation-data-type=ADS_Authernticator_1BA_datatype, to GW
          signal ADS_MesssageCounter_1BA: start 251, 6 bit, big-endian, base-type=uint8, compu {texttable}, implementation-data-type=ADS_MesssageCounter_1BA_datatype, to GW
          signal ADS_ResetFlag_1BA: start 193, 2 bit, big-endian, base-type=uint8, compu {texttable}, implementation-data-type=ADS_ResetFlag_1BA_datatype, to GW
      frame ADC_244: id 0x244, from ADC, to GW VCU, frame-length=8, can-addressing-mode=STANDARD
        pdu ADC_244: length=1
          signal ACC_ACCMode: start 54, 3 bit, big-endian, base-type=uint8, compu {identical}, implementation-data-type=ACC_ACCMode_datatype, to GW VCU
          signal ACC_ACCTargetAcceleration: start 7, 8 bit, big-endian, base-type=uint8, compu {texttable; unit m/s2}, implementation-data-type=ACC_ACCTargetAcceleration_datatype, to GW
          signal ACC_AWBlevel: start 57, 4 bit, big-endian, base-type=uint8, compu {identical}, implementation-data-type=ACC_AWBlevel_datatype, to GW
          signal ACC_AccTrqReq: start 52, 15 bit, big-endian, base-type=uint16, compu {texttable; unit Nm}, implementation-data-type=ACC_AccTrqReq_datatype, to VCU
          signal ACC_AccTrqReqActive: start 70, 1 bit, big-endian, base-type=uint8, compu {identical}, implementation-data-type=ACC_AccTrqReqActive_datatype, to VCU
          signal ACC_CDDActive: start 44, 1 bit, big-endian, base-type=uint8, compu {identical}, implementation-data-type=ACC_CDDActive_datatype, to GW
          signal ACC_CRCCheck_24E: start 63, 8 bit, big-endian, base-type=uint8, compu {texttable}, implementation-data-type=ACC_CRCCheck_24E_datatype, to VCU
          signal ACC_CRCCheck_25E: start 61, 8 bit, big-endian, base-type=uint8, compu {texttable}, implementation-data-type=ACC_CRCCheck_25E_datatype, to VCU
          signal ACC_DecToStop: start 31, 1 bit, big-endian, base-type=uint8, compu {identical}, implementation-data-type=ACC_DecToStop_datatype, to GW
          signal ACC_Driveoff_Request: start 55, 1 bit, big-endian, base-type=uint8, compu {identical}, implementation-data-type=ACC_Driveoff_Request_datatype, to GW VCU
          signal ACC_RollingCounter_24E: start 51, 4 bit, big-endian, base-type=uint8, compu {texttable}, implementation-data-type=ACC_RollingCounter_24E_datatype, to VCU
          signal ACC_RollingCounter_25E: start 57, 4 bit, big-endian, base-type=uint8, compu {texttable}, implementation-data-type=ACC_RollingCounter_25E_datatype, to VCU
          signal ADS_Authernticator_244: start 13, 56 bit, big-endian, compu {texttable}, implementation-data-type=ADS_Authernticator_244_datatype, to GW
          signal ADS_CRCCheck_244: start 53, 16 bit, big-endian, base-type=uint16, compu {texttable}, implementation-data-type=ADS_CRCCheck_244_datatype, to GW
          signal ADS_MesssageCounter_244: start 59, 6 bit, big-endian, base-type=uint8, compu {texttable}, implementation-data-type=ADS_MesssageCounter_244_datatype, to GW
          signal ADS_ResetFlag_244: start 71, 2 bit, big-endian, base-type=uint8, compu {texttable}, implementation-data-type=ADS_ResetFlag_244_datatype, to GW
          signal ADS_RollingCounter_244: start 57, 4 bit, big-endian, base-type=uint8, compu {texttable}, implementation-data-type=ADS_RollingCounter_244_datatype, to GW
      frame ADC_307: id 0x307, from ADC, to GW, frame-length=64, can-addressing-mode=STANDARD
        pdu ADC_307: length=8
          signal ACC_ACCEPBrequest: start 23, 1 bit, big-endian, base-type=uint8, compu {identical}, implementation-data-type=ACC_ACCEPBrequest_datatype, to GW
          signal ACC_ACCTargetDirection: start 104, 3 bit, big-endian, base-type=uint8, compu {identical}, implementation-data-type=ACC_ACCTargetDirection_datatype, to GW
          signal ACC_ACCTargetLatRange: start 99, 10 bit, big-endian, base-type=uint16, compu {texttable; unit m}, implementation-data-type=ACC_ACCTargetLatRange_datatype, to GW
          signal ACC_ACCTargetLngRange: start 71, 9 bit, big-endian, base-type=uint16, compu {texttable; unit m}, implementation-data-type=ACC_ACCTargetLngRange_datatype, to GW
          signal ACC_ACCTargetRelSpd: start 92, 9 bit, big-endian, base-type=uint16, compu {texttable; unit km/h}, implementation-data-type=ACC_ACCTargetRelSpd_datatype, to GW
          signal ACC_ACCTargetType: start 78, 4 bit, big-endian, base-type=uint8, compu {identical}, implementation-data-type=ACC_ACCTargetType_datatype, to GW
          signal ACC_CRCCheck_307: start 503, 16 bit, big-endian, base-type=uint16, compu {texttable}, implementation-data-type=ACC_CRCCheck_307_datatype, to GW
          signal ACC_CRCCheck_322: start 127, 8 bit, big-endian, base-type=uint8, compu {texttable}, implementation-data-type=ACC_CRCCheck_322_datatype
          signal ACC_CRCCheck_344: start 191, 8 bit, big-endian, base-type=uint8, compu {texttable}, implementation-data-type=ACC_CRCCheck_344_datatype
          signal ACC_CRCCheck_35E: start 63, 8 bit, big-endian, base-type=uint8, compu {texttable}, implementation-data-type=ACC_CRCCheck_35E_datatype
          signal ACC_CRCCheck_35F: start 255, 8 bit, big-endian, base-type=uint8, compu {texttable}, implementation-data-type=ACC_CRCCheck_35F_datatype
          signal ACC_DistanceLevel: start 22, 3 bit, big-endian, base-type=uint8, compu {identical}, implementation-data-type=ACC_DistanceLevel_datatype, to GW
          signal ACC_LngTakeOverReq: start 12, 2 bit, big-endian, base-type=uint8, compu {identical}, implementation-data-type=ACC_LngTakeOverReq_datatype, to GW
          signal ACC_ObjValid: start 13, 1 bit, big-endian, base-type=uint8, compu {identical}, implementation-data-type=ACC_ObjValid_datatype, to GW
          signal ACC_RollingCounter_307: start 491, 4 bit, big-endian, base-type=uint8, compu {texttable}, implementation-data-type=ACC_RollingCounter_307_datatype, to GW
          signal ACC_RollingCounter_322: start 115, 4 bit, big-endian, base-type=uint8, compu {texttable}, implementation-data-type=ACC_RollingCounter_322_datatype
          signal ACC_RollingCounter_344: start 179, 4 bit, big-endian, base-type=uint8, compu {texttable}, implementation-data-type=ACC_RollingCounter_344_datatype
          signal ACC_RollingCounter_35E: start 51, 4 bit, big-endian, base-type=uint8, compu {texttable}, implementation-data-type=ACC_RollingCounter_35E_datatype
          signal ACC_RollingCounter_35F: start 243, 4 bit, big-endian, base-type=uint8, compu {texttable}, implementation-data-type=ACC_RollingCounter_35F_datatype
          signal ACC_SaftyBeltVibrationReq: start 42, 1 bit, big-endian, base-type=uint8, compu {identical}, implementation-data-type=ACC_SaftyBeltVibrationReq_datatype
          signal ACC_SaftyBelt_Tightened: start 41, 2 bit, big-endian, base-type=uint8, compu {identical}, implementation-data-type=ACC_SaftyBelt_Tightened_datatype
          signal ACC_SetSpeed: start 6, 8 bit, big-endian, base-type=uint8, compu {texttable; unit Km/h}, implementation-data-type=ACC_SetSpeed_datatype, to GW
          signal ACC_TextInfoForDriver: start 84, 5 bit, big-endian, base-type=uint8, compu {identical}, implementation-data-type=ACC_TextInfoForDriver_datatype, to GW
          signal ACC_TimeGapSet: start 18, 3 bit, big-endian, base-type=uint8, compu {identical}, implementation-data-type=ACC_TimeGapSet_datatype, to GW
      frame ADC_312: id 0x312, from ADC, to FC_Public GW, frame-length=64, can-addressing-mode=STANDARD
        pdu ADC_312: length=8
          signal ACC_ACCTargetID: start 6, 4 bit, big-endian, base-type=uint8, compu {texttable}, implementation-data-type=ACC_ACCTargetID_datatype, to GW
          signal ACC_CRCCheck_3E4: start 63, 8 bit, big-endian, base-type=uint8, compu {texttable}, implementation-data-type=ACC_CRCCheck_3E4_datatype, to FC_Public GW
          signal ACC_LLaneDistanceFusion: start 30, 7 bit, big-endian, base-type=uint8, compu {texttable; unit m}, implementation-data-type=ACC_LLaneDistanceFusion_datatype, to GW
          signal ACC_RLaneDistanceFusion: start 38, 7 bit, big-endian, base-type=uint8, compu {texttable; unit m}, implementation-data-type=ACC_RLaneDistanceFusion_datatype, to GW
          signal ACC_RollingCounter_3E4: start 51, 4 bit, big-endian, base-type=uint8, compu {texttable}, implementation-data-type=ACC_RollingCounter_3E4_datatype, to GW
          signal ADS_CRCCheck_312: start 503, 16 bit, big-endian, base-type=uint16, compu {texttable}, implementation-data-type=ADS_CRCCheck_312_datatype, to FC_Public GW
          signal ADS_RollingCounter_312: start 491, 4 bit, big-endian, base-type=uint8, compu {texttable}, implementation-data-type=ADS_RollingCounter_312_datatype, to FC_Public GW
      frame ADC_31A: id 0x31A, from ADC, to FC_Public GW, frame-length=64, can-addressing-mode=STANDARD
        pdu ADC_31A: length=8
          signal ACC_CRCCheck_30A: start 127, 8 bit, big-endian, base-type=uint8, compu {texttable}, implementation-data-type=ACC_CRCCheck_30A_datatype, to FC_Public GW
          signal ACC_CRCCheck_30D: start 191, 8 bit, big-endian, base-type=uint8, compu {texttable}, implementation-data-type=ACC_CRCCheck_30D_datatype, to GW
          signal ACC_CRCCheck_31A: start 503, 16 bit, big-endian, base-type=uint16, compu {texttable}, implementation-data-type=ACC_CRCCheck_31A_datatype, to FC_Public GW
          signal ACC_CRCCheck_367: start 255, 8 bit, big-endian, base-type=uint8, compu {texttable}, implementation-data-type=ACC_CRCCheck_367_datatype, to GW
          signal ACC_CRCCheck_36D: start 63, 8 bit, big-endian, base-type=uint8, compu {texttable}, implementation-data-type=ACC_CRCCheck_36D_datatype, to FC_Public GW
          signal ACC_DriverHandsOffStatus: start 137, 2 bit, big-endian, base-type=uint8, compu {identical}, implementation-data-type=ACC_DriverHandsOffStatus_datatype, to FC_Public GW
          signal ACC_EmergencyLightingRequest: start 148, 2 bit, big-endian, base-type=uint8, compu {identical}, implementation-data-type=ACC_EmergencyLightingRequest_datatype, to GW
          signal ACC_HandsOnReq: start 130, 3 bit, big-endian, base-type=uint8, compu {identical}, implementation-data-type=ACC_HandsOnReq_datatype, to GW
          signal ACC_HostLaneLeftStatus: start 83, 4 bit, big-endian, base-type=uint8, compu {identical}, implementation-data-type=ACC_HostLaneLeftStatus_datatype, to GW
          signal ACC_HostLaneRightStatus: start 87, 4 bit, big-endian, base-type=uint8, compu {identical}, implementation-data-type=ACC_HostLaneRightStatus_datatype, to GW
          signal ACC_IACCHWAMode: start 135, 3 bit, big-endian, base-type=uint8, compu {identical}, implementation-data-type=ACC_IACCHWAMode_datatype, to FC_Public GW
          signal ACC_IACCHWATextInfoForDriver: start 143, 5 bit, big-endian, base-type=uint8, compu {identical}, implementation-data-type=ACC_IACCHWATextInfoForDriver_datatype, to GW
          signal ACC_LatTakeoverReq: start 132, 2 bit, big-endian, base-type=uint8, compu {identical}, implementation-data-type=ACC_LatTakeoverReq_datatype, to GW
          signal ACC_RollingCounter_30A: start 115, 4 bit, big-endian, base-type=uint8, compu {texttable}, implementation-data-type=ACC_RollingCounter_30A_datatype, to GW
          signal ACC_RollingCounter_30D: start 179, 4 bit, big-endian, base-type=uint8, compu {texttable}, implementation-data-type=ACC_RollingCounter_30D_datatype, to GW
          signal ACC_RollingCounter_31A: start 491, 4 bit, big-endian, base-type=uint8, compu {texttable}, implementation-data-type=ACC_RollingCounter_31A_datatype, to FC_Public GW
          signal ACC_RollingCounter_367: start 243, 4 bit, big-endian, base-type=uint8, compu {texttable}, implementation-data-type=ACC_RollingCounter_367_datatype, to GW
          signal ACC_RollingCounter_36D: start 51, 4 bit, big-endian, base-type=uint8, compu {texttable}, implementation-data-type=ACC_RollingCounter_36D_datatype, to GW
          signal ACC_TargetBasedLateralControl: start 150, 2 bit, big-endian, base-type=uint8, compu {identical}, implementation-data-type=ACC_TargetBasedLateralControl_datatype, to GW
          signal ACC_Voiceinfo: start 47, 5 bit, big-endian, base-type=uint8, compu {identical}, implementation-data-type=ACC_Voiceinfo_datatype, to GW
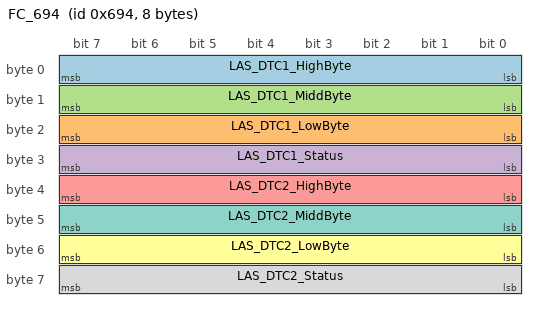
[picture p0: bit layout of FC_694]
      frame FC_694: id 0x694, from FC_Public, to TBOX, frame-length=8, can-addressing-mode=STANDARD
        pdu FC_694: length=1
          signal LAS_DTC1_HighByte: start 7, 8 bit, big-endian, base-type=uint8, compu {texttable}, implementation-data-type=LAS_DTC1_HighByte_datatype, to TBOX
          signal LAS_DTC1_LowByte: start 23, 8 bit, big-endian, base-type=uint8, compu {texttable}, implementation-data-type=LAS_DTC1_LowByte_datatype, to TBOX
          signal LAS_DTC1_MiddByte: start 15, 8 bit, big-endian, base-type=uint8, compu {texttable}, implementation-data-type=LAS_DTC1_MiddByte_datatype, to TBOX
          signal LAS_DTC1_Status: start 31, 8 bit, big-endian, base-type=uint8, compu {texttable}, implementation-data-type=LAS_DTC1_Status_datatype, to TBOX
          signal LAS_DTC2_HighByte: start 39, 8 bit, big-endian, base-type=uint8, compu {texttable}, implementation-data-type=LAS_DTC2_HighByte_datatype, to TBOX
          signal LAS_DTC2_LowByte: start 55, 8 bit, big-endian, base-type=uint8, compu {texttable}, implementation-data-type=LAS_DTC2_LowByte_datatype, to TBOX
          signal LAS_DTC2_MiddByte: start 47, 8 bit, big-endian, base-type=uint8, compu {texttable}, implementation-data-type=LAS_DTC2_MiddByte_datatype, to TBOX
          signal LAS_DTC2_Status: start 63, 8 bit, big-endian, base-type=uint8, compu {texttable}, implementation-data-type=LAS_DTC2_Status_datatype, to TBOX
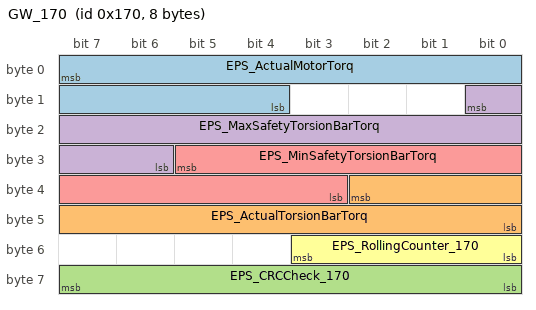
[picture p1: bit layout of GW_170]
      frame GW_170: id 0x170, from GW, to ADC FC_Public, frame-length=8, can-addressing-mode=STANDARD
        pdu GW_170: length=1
          signal EPS_ActualMotorTorq: start 7, 12 bit, big-endian, base-type=uint16, compu {texttable; unit Nm}, implementation-data-type=EPS_ActualMotorTorq_datatype, to ADC FC_Public
          signal EPS_ActualTorsionBarTorq: start 34, 11 bit, big-endian, base-type=uint16, compu {texttable; unit Nm}, implementation-data-type=EPS_ActualTorsionBarTorq_datatype, to ADC FC_Public
          signal EPS_CRCCheck_170: start 63, 8 bit, big-endian, base-type=uint8, compu {texttable}, implementation-data-type=EPS_CRCCheck_170_datatype, to ADC FC_Public
          signal EPS_MaxSafetyTorsionBarTorq: start 8, 11 bit, big-endian, base-type=uint16, compu {texttable; unit Nm}, implementation-data-type=EPS_MaxSafetyTorsionBarTorq_datatype, to ADC FC_Public
          signal EPS_MinSafetyTorsionBarTorq: start 29, 11 bit, big-endian, base-type=uint16, compu {texttable; unit Nm}, implementation-data-type=EPS_MinSafetyTorsionBarTorq_datatype, to ADC FC_Public
          signal EPS_RollingCounter_170: start 51, 4 bit, big-endian, base-type=uint8, compu {texttable}, implementation-data-type=EPS_RollingCounter_170_datatype, to ADC FC_Public
      frame GW_17A: id 0x17A, from GW, to ADC FC_Public, frame-length=64, can-addressing-mode=STANDARD
        pdu GW_17A: length=8
          signal EPB_APArequest_Available: start 64, 1 bit, big-endian, base-type=uint8, compu {identical}, implementation-data-type=EPB_APArequest_Available_datatype, to ADC FC_Public
          signal EPB_AchievedClampForce: start 85, 5 bit, big-endian, base-type=uint8, compu {texttable; unit KN}, implementation-data-type=EPB_AchievedClampForce_datatype, to ADC FC_Public
          signal EPB_AchievedClampForce_Primary: start 69, 5 bit, big-endian, base-type=uint8, compu {texttable; unit KN}, implementation-data-type=EPB_AchievedClampForce_Primary_datatype, to ADC FC_Public
          signal EPB_FailStatuss_Primary: start 87, 2 bit, big-endian, base-type=uint8, compu {identical}, implementation-data-type=EPB_FailStatuss_Primary_datatype, to ADC FC_Public
          signal ESP_CRCCheck_17A: start 503, 16 bit, big-endian, base-type=uint16, compu {texttable}, implementation-data-type=ESP_CRCCheck_17A_datatype, to ADC FC_Public
          signal ESP_RollingCounter_17A: start 491, 4 bit, big-endian, base-type=uint8, compu {texttable}, implementation-data-type=ESP_RollingCounter_17A_datatype, to ADC FC_Public
          signal EspVehSpd: start 36, 13 bit, big-endian, base-type=uint16, compu {texttable; unit km/h}, implementation-data-type=EspVehSpd_datatype, to ADC FC_Public
          signal EspVehSpdVld: start 37, 1 bit, big-endian, base-type=uint8, compu {identical}, implementation-data-type=EspVehSpdVld_datatype, to ADC FC_Public
          signal IBCU_PFSBrakePressure: start 15, 12 bit, big-endian, base-type=uint16, compu {texttable; unit bar}, implementation-data-type=IBCU_PFSBrakePressure_datatype, to ADC FC_Public
          signal IBCU_PFSBrakePressureValid: start 38, 1 bit, big-endian, base-type=uint8, compu {identical}, implementation-data-type=IBCU_PFSBrakePressureValid_datatype, to ADC FC_Public
          signal IBCU_PlungerBrakePressure: start 19, 12 bit, big-endian, base-type=uint16, compu {texttable; unit bar}, implementation-data-type=IBCU_PlungerBrakePressure_datatype, to ADC FC_Public
          signal IBCU_PlungerBrakePressureValid: start 39, 1 bit, big-endian, base-type=uint8, compu {identical}, implementation-data-type=IBCU_PlungerBrakePressureValid_datatype, to ADC FC_Public
          signal WheelPressureFrontLeft_Model: start 467, 12 bit, big-endian, base-type=uint16, compu {texttable; unit bar}, implementation-data-type=WheelPressureFrontLeft_Model_datatype, to ADC FC_Public
          signal WheelPressureFrontRight_Model: start 95, 12 bit, big-endian, base-type=uint16, compu {texttable; unit bar}, implementation-data-type=WheelPressureFrontRight_Model_datatype, to ADC FC_Public
          signal WheelPressureRearLeft_Model: start 99, 12 bit, big-endian, base-type=uint16, compu {texttable; unit bar}, implementation-data-type=WheelPressureRearLeft_Model_datatype, to ADC FC_Public
          signal WheelPressureRearRight_Model: start 119, 12 bit, big-endian, base-type=uint16, compu {texttable; unit bar}, implementation-data-type=WheelPressureRearRight_Model_datatype, to ADC FC_Public
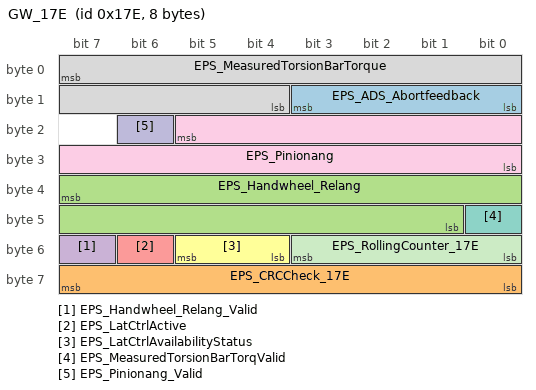
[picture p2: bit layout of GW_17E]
      frame GW_17E: id 0x17E, from GW, to ADC FC_Public, frame-length=8, can-addressing-mode=STANDARD
        pdu GW_17E: length=1
          signal EPS_ADS_Abortfeedback: start 11, 4 bit, big-endian, base-type=uint8, compu {identical}, implementation-data-type=EPS_ADS_Abortfeedback_datatype, to ADC
          signal EPS_CRCCheck_17E: start 63, 8 bit, big-endian, base-type=uint8, compu {texttable}, implementation-data-type=EPS_CRCCheck_17E_datatype, to ADC FC_Public
          signal EPS_Handwheel_Relang: start 39, 15 bit, big-endian, base-type=uint16, compu {texttable; unit degree}, implementation-data-type=EPS_Handwheel_Relang_datatype, to ADC FC_Public
          signal EPS_Handwheel_Relang_Valid: start 55, 1 bit, big-endian, base-type=uint8, compu {identical}, implementation-data-type=EPS_Handwheel_Relang_Valid_datatype, to ADC FC_Public
          signal EPS_LatCtrlActive: start 54, 1 bit, big-endian, base-type=uint8, compu {identical}, implementation-data-type=EPS_LatCtrlActive_datatype, to ADC FC_Public
          signal EPS_LatCtrlAvailabilityStatus: start 53, 2 bit, big-endian, base-type=uint8, compu {identical}, implementation-data-type=EPS_LatCtrlAvailabilityStatus_datatype, to ADC FC_Public
          signal EPS_MeasuredTorsionBarTorqValid: start 40, 1 bit, big-endian, base-type=uint8, compu {identical}, implementation-data-type=EPS_MeasuredTorsionBarTorqValid_datatype, to ADC FC_Public
          signal EPS_MeasuredTorsionBarTorque: start 7, 12 bit, big-endian, base-type=uint16, compu {texttable; unit Nm}, implementation-data-type=EPS_MeasuredTorsionBarTorque_datatype, to ADC FC_Public
          signal EPS_Pinionang: start 21, 14 bit, big-endian, base-type=uint16, compu {texttable; unit degree}, implementation-data-type=EPS_Pinionang_datatype, to ADC FC_Public
          signal EPS_Pinionang_Valid: start 22, 1 bit, big-endian, base-type=uint8, compu {identical}, implementation-data-type=EPS_Pinionang_Valid_datatype, to ADC FC_Public
          signal EPS_RollingCounter_17E: start 51, 4 bit, big-endian, base-type=uint8, compu {texttable}, implementation-data-type=EPS_RollingCounter_17E_datatype, to ADC FC_Public
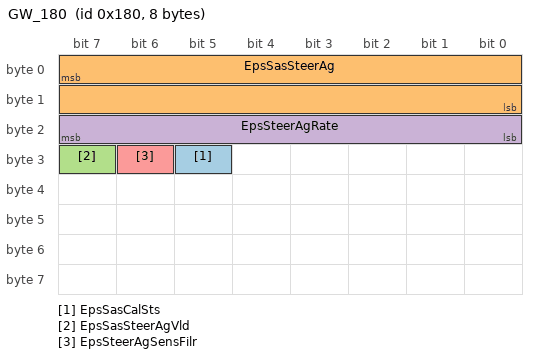
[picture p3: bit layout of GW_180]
      frame GW_180: id 0x180, from GW, to ADC FC_Public, frame-length=8, can-addressing-mode=STANDARD
        pdu GW_180: length=1
          signal EpsSasCalSts: start 29, 1 bit, big-endian, base-type=uint8, compu {identical}, implementation-data-type=EpsSasCalSts_datatype, to ADC FC_Public
          signal EpsSasSteerAg: start 7, 16 bit, big-endian, base-type=sint16, compu {texttable; unit degree}, implementation-data-type=EpsSasSteerAg_datatype, to ADC FC_Public
          signal EpsSasSteerAgVld: start 31, 1 bit, big-endian, base-type=uint8, compu {identical}, implementation-data-type=EpsSasSteerAgVld_datatype, to ADC FC_Public
          signal EpsSteerAgRate: start 23, 8 bit, big-endian, base-type=uint8, compu {texttable; unit deg/s}, implementation-data-type=EpsSteerAgRate_datatype, to ADC FC_Public
          signal EpsSteerAgSensFilr: start 30, 1 bit, big-endian, base-type=uint8, compu {identical}, implementation-data-type=EpsSteerAgSensFilr_datatype, to ADC FC_Public
      frame GW_1C2: id 0x1C2, from GW, to ADC FC_Public, frame-length=64, can-addressing-mode=STANDARD
        pdu GW_1C2: length=8
          signal EspAbsActv: start 72, 1 bit, big-endian, base-type=uint8, compu {identical}, implementation-data-type=EspAbsActv_datatype, to ADC FC_Public
          signal EspAbsFailr: start 73, 1 bit, big-endian, base-type=uint8, compu {identical}, implementation-data-type=EspAbsFailr_datatype, to ADC FC_Public
          signal EspActvSts: start 55, 1 bit, big-endian, base-type=uint8, compu {identical}, implementation-data-type=EspActvSts_datatype, to ADC FC_Public
          signal EspAutoHoldActvSts: start 353, 2 bit, big-endian, base-type=uint8, compu {identical}, implementation-data-type=EspAutoHoldActvSts_datatype, to ADC FC_Public
          signal EspCrcChk1C2: start 503, 16 bit, big-endian, base-type=uint16, compu {texttable}, implementation-data-type=EspCrcChk1C2_datatype, to ADC FC_Public
          signal EspCycCntr1C2: start 491, 4 bit, big-endian, base-type=uint8, compu {texttable}, implementation-data-type=EspCycCntr1C2_datatype, to ADC FC_Public
          signal EspEbdFailr: start 87, 1 bit, big-endian, base-type=uint8, compu {identical}, implementation-data-type=EspEbdFailr_datatype, to ADC FC_Public
          signal EspFctOpenSts: start 54, 1 bit, big-endian, base-type=uint8, compu {identical}, implementation-data-type=EspFctOpenSts_datatype, to ADC FC_Public
          signal EspReWhlDecTarTq: start 271, 16 bit, big-endian, base-type=uint16, compu {texttable; unit Nm}, implementation-data-type=EspReWhlDecTarTq_datatype, to ADC FC_Public
          signal EspReWhlDecTarTqActv: start 38, 1 bit, big-endian, base-type=uint8, compu {identical}, implementation-data-type=EspReWhlDecTarTqActv_datatype, to ADC FC_Public
          signal EspReWhlIncTarTq: start 335, 16 bit, big-endian, base-type=uint16, compu {texttable; unit Nm}, implementation-data-type=EspReWhlIncTarTq_datatype, to ADC FC_Public
          signal EspReWhlIncTarTqActv: start 37, 1 bit, big-endian, base-type=uint8, compu {identical}, implementation-data-type=EspReWhlIncTarTqActv_datatype, to ADC FC_Public
          signal EspTcsFailr: start 53, 1 bit, big-endian, base-type=uint8, compu {identical}, implementation-data-type=EspTcsFailr_datatype, to ADC FC_Public
          signal EspVehStandstill: start 351, 1 bit, big-endian, base-type=uint8, compu {identical}, implementation-data-type=EspVehStandstill_datatype, to ADC FC_Public
          signal IBCU_BrakeDiscHighTempWarning: start 1, 2 bit, big-endian, base-type=uint8, compu {identical}, implementation-data-type=IBCU_BrakeDiscHighTempWarning_datatype, to ADC FC_Public
          signal MbRgnTarWhl: start 423, 16 bit, big-endian, base-type=uint16, compu {texttable; unit Nm}, implementation-data-type=MbRgnTarWhl_datatype, to ADC FC_Public
          signal MbRgnTarWhlQlfr: start 413, 2 bit, big-endian, base-type=uint8, compu {identical}, implementation-data-type=MbRgnTarWhlQlfr_datatype, to ADC FC_Public
      frame GW_20B: id 0x20B, from GW, to ADC FC_Public, frame-length=64, can-addressing-mode=STANDARD
        pdu GW_20B: length=8
          signal ESP_ABAactive: start 262, 1 bit, big-endian, base-type=uint8, compu {identical}, implementation-data-type=ESP_ABAactive_datatype, to ADC
          signal ESP_ABAavailable: start 261, 1 bit, big-endian, base-type=uint8, compu {identical}, implementation-data-type=ESP_ABAavailable_datatype, to ADC
          signal ESP_AEBAvailable: start 258, 1 bit, big-endian, base-type=uint8, compu {identical}, implementation-data-type=ESP_AEBAvailable_datatype, to ADC
          signal ESP_AEBdecActive: start 257, 1 bit, big-endian, base-type=uint8, compu {identical}, implementation-data-type=ESP_AEBdecActive_datatype, to ADC
          signal ESP_APAFailureSts: start 37, 4 bit, big-endian, base-type=uint8, compu {identical}, implementation-data-type=ESP_APAFailureSts_datatype, to ADC FC_Public
          signal ESP_APAStatus: start 33, 2 bit, big-endian, base-type=uint8, compu {identical}, implementation-data-type=ESP_APAStatus_datatype, to ADC
          signal ESP_APA_CDDAPVehicleHold: start 283, 1 bit, big-endian, base-type=uint8, compu {identical}, implementation-data-type=ESP_APA_CDDAPVehicleHold_datatype, to ADC
          signal ESP_APA_DriverOverride: start 119, 1 bit, big-endian, base-type=uint8, compu {identical}, implementation-data-type=ESP_APA_DriverOverride_datatype, to ADC
          signal ESP_AWBactive: start 256, 1 bit, big-endian, base-type=uint8, compu {identical}, implementation-data-type=ESP_AWBactive_datatype, to ADC
          signal ESP_AWBavailable: start 271, 1 bit, big-endian, base-type=uint8, compu {identical}, implementation-data-type=ESP_AWBavailable_datatype, to ADC
          signal ESP_Available_ReducedFunction: start 276, 1 bit, big-endian, base-type=uint8, compu {identical}, implementation-data-type=ESP_Available_ReducedFunction_datatype, to ADC
          signal ESP_BrakeForce: start 263, 1 bit, big-endian, base-type=uint8, compu {identical}, implementation-data-type=ESP_BrakeForce_datatype, to ADC
          signal ESP_BrakeOverHeatBrakeDiscTemp: start 270, 1 bit, big-endian, base-type=uint8, compu {identical}, implementation-data-type=ESP_BrakeOverHeatBrakeDiscTemp_datatype, to ADC
          signal ESP_CDD_Active: start 269, 1 bit, big-endian, base-type=uint8, compu {identical}, implementation-data-type=ESP_CDD_Active_datatype, to ADC
          signal ESP_CDD_Available: start 268, 1 bit, big-endian, base-type=uint8, compu {identical}, implementation-data-type=ESP_CDD_Available_datatype, to ADC
          signal ESP_PrefillActive: start 260, 1 bit, big-endian, base-type=uint8, compu {identical}, implementation-data-type=ESP_PrefillActive_datatype, to ADC
          signal ESP_PrefillAvailable: start 259, 1 bit, big-endian, base-type=uint8, compu {identical}, implementation-data-type=ESP_PrefillAvailable_datatype, to ADC
          signal ESP_PrefillforAPA_Available: start 113, 1 bit, big-endian, base-type=uint8, compu {identical}, implementation-data-type=ESP_PrefillforAPA_Available_datatype, to ADC
          signal ESP_PrefillforAPA_active: start 112, 1 bit, big-endian, base-type=uint8, compu {identical}, implementation-data-type=ESP_PrefillforAPA_active_datatype, to ADC
          signal ESP_QDCACC: start 279, 2 bit, big-endian, base-type=uint8, compu {identical}, implementation-data-type=ESP_QDCACC_datatype, to ADC
          signal ESP_UrgencyBrakeAlarm: start 118, 1 bit, big-endian, base-type=uint8, compu {identical}, implementation-data-type=ESP_UrgencyBrakeAlarm_datatype, to ADC
          signal ESP__Available_FullFunction: start 281, 2 bit, big-endian, base-type=uint8, compu {identical}, implementation-data-type=ESP__Available_FullFunction_datatype, to ADC
          signal EspBrkLiOnReq: start 197, 2 bit, big-endian, base-type=uint8, compu {identical}, implementation-data-type=EspBrkLiOnReq_datatype, to ADC
          signal IBCU_CDDAvailableStatus: start 275, 2 bit, big-endian, base-type=uint8, compu {identical}, implementation-data-type=IBCU_CDDAvailableStatus_datatype, to ADC
          signal Wheel_SpeedPulseTimeStamp_FL: start 167, 16 bit, big-endian, base-type=uint16, compu {texttable; unit ms}, implementation-data-type=Wheel_SpeedPulseTimeStamp_FL_datatype, to ADC FC_Public
          signal Wheel_SpeedPulseTimeStamp_FR: start 143, 16 bit, big-endian, base-type=uint16, compu {texttable; unit ms}, implementation-data-type=Wheel_SpeedPulseTimeStamp_FR_datatype, to ADC FC_Public
          signal WhlSpdFrntLePls: start 215, 8 bit, big-endian, base-type=uint8, compu {texttable}, implementation-data-type=WhlSpdFrntLePls_datatype, to ADC FC_Public
          signal WhlSpdFrntRiPls: start 223, 8 bit, big-endian, base-type=uint8, compu {texttable}, implementation-data-type=WhlSpdFrntRiPls_datatype, to ADC FC_Public
          signal WhlSpdLeFrntData: start 20, 13 bit, big-endian, base-type=uint16, compu {texttable; unit km/h}, implementation-data-type=WhlSpdLeFrntData_datatype, to ADC FC_Public
          signal WhlSpdLeFrntDataVld: start 23, 1 bit, big-endian, base-type=uint8, compu {identical}, implementation-data-type=WhlSpdLeFrntDataVld_datatype, to ADC FC_Public
          signal WhlSpdLeFrntDir: start 22, 2 bit, big-endian, base-type=uint8, compu {identical}, implementation-data-type=WhlSpdLeFrntDir_datatype, to ADC FC_Public
          signal WhlSpdLeReData: start 84, 13 bit, big-endian, base-type=uint16, compu {texttable; unit km/h}, implementation-data-type=WhlSpdLeReData_datatype, to ADC FC_Public
          signal WhlSpdLeReDataVld: start 87, 1 bit, big-endian, base-type=uint8, compu {identical}, implementation-data-type=WhlSpdLeReDataVld_datatype, to ADC FC_Public
          signal WhlSpdLeReDir: start 86, 2 bit, big-endian, base-type=uint8, compu {identical}, implementation-data-type=WhlSpdLeReDir_datatype, to ADC FC_Public
          signal WhlSpdReLePls: start 239, 8 bit, big-endian, base-type=uint8, compu {texttable}, implementation-data-type=WhlSpdReLePls_datatype, to ADC FC_Public
          signal WhlSpdReRiPls: start 231, 8 bit, big-endian, base-type=uint8, compu {texttable}, implementation-data-type=WhlSpdReRiPls_datatype, to ADC FC_Public
          signal WhlSpdRiFrntData: start 4, 13 bit, big-endian, base-type=uint16, compu {texttable; unit km/h}, implementation-data-type=WhlSpdRiFrntData_datatype, to ADC FC_Public
          signal WhlSpdRiFrntDataVld: start 7, 1 bit, big-endian, base-type=uint8, compu {identical}, implementation-data-type=WhlSpdRiFrntDataVld_datatype, to ADC FC_Public
          signal WhlSpdRiFrntDir: start 6, 2 bit, big-endian, base-type=uint8, compu {identical}, implementation-data-type=WhlSpdRiFrntDir_datatype, to ADC FC_Public
          signal WhlSpdRiReData: start 68, 13 bit, big-endian, base-type=uint16, compu {texttable; unit km/h}, implementation-data-type=WhlSpdRiReData_datatype, to ADC FC_Public
          signal WhlSpdRiReDataVld: start 71, 1 bit, big-endian, base-type=uint8, compu {identical}, implementation-data-type=WhlSpdRiReDataVld_datatype, to ADC FC_Public
          signal WhlSpdRiReDir: start 70, 2 bit, big-endian, base-type=uint8, compu {identical}, implementation-data-type=WhlSpdRiReDir_datatype, to ADC FC_Public
      frame GW_22B: id 0x22B, from GW, to ADC, frame-length=64, can-addressing-mode=STANDARD
        pdu GW_22B: length=8
          signal RBM_CDD_Active_APA: start 32, 1 bit, big-endian, base-type=uint8, compu {identical}, implementation-data-type=RBM_CDD_Active_APA_datatype, to ADC
          signal RBM_CDD_Available_APA: start 471, 1 bit, big-endian, base-type=uint8, compu {identical}, implementation-data-type=RBM_CDD_Available_APA_datatype, to ADC
          signal RBM_FailStatus: start 408, 1 bit, big-endian, base-type=uint8, compu {identical}, implementation-data-type=RBM_FailStatus_datatype, to ADC
          signal RbmCrcChk22B: start 503, 16 bit, big-endian, base-type=uint16, compu {texttable}, implementation-data-type=RbmCrcChk22B_datatype, to ADC
          signal RbmCycCntr22B: start 491, 4 bit, big-endian, base-type=uint8, compu {texttable}, implementation-data-type=RbmCycCntr22B_datatype, to ADC
          signal RbmEPBCoordination_Secondary: start 423, 16 bit, big-endian, base-type=uint16, compu {texttable}, implementation-data-type=RbmEPBCoordination_Secondary_datatype, to ADC
          signal RbmEPBSafetyLimiterState_Seconda: start 474, 1 bit, big-endian, base-type=uint8, compu {texttable}, implementation-data-type=RbmEPBSafetyLimiterState_Seconda_datatype, to ADC
          signal RbmEPB_AchievedClampForce_Second: start 470, 5 bit, big-endian, base-type=uint8, compu {texttable; unit KN}, implementation-data-type=RbmEPB_AchievedClampForce_Second_datatype, to ADC
          signal RbmEPB_FailStatuss_Secondary: start 465, 2 bit, big-endian, base-type=uint8, compu {identical}, implementation-data-type=RbmEPB_FailStatuss_Secondary_datatype, to ADC
          signal RbmESP_ABAactive: start 262, 1 bit, big-endian, base-type=uint8, compu {identical}, implementation-data-type=RbmESP_ABAactive_datatype, to ADC
          signal RbmESP_ABAavailable: start 261, 1 bit, big-endian, base-type=uint8, compu {identical}, implementation-data-type=RbmESP_ABAavailable_datatype, to ADC
          signal RbmESP_AEBAvailable: start 258, 1 bit, big-endian, base-type=uint8, compu {identical}, implementation-data-type=RbmESP_AEBAvailable_datatype, to ADC
          signal RbmESP_AEBdecActive: start 257, 1 bit, big-endian, base-type=uint8, compu {identical}, implementation-data-type=RbmESP_AEBdecActive_datatype, to ADC
          signal RbmESP_AWBactive: start 256, 1 bit, big-endian, base-type=uint8, compu {identical}, implementation-data-type=RbmESP_AWBactive_datatype, to ADC
          signal RbmESP_AWBavailable: start 271, 1 bit, big-endian, base-type=uint8, compu {identical}, implementation-data-type=RbmESP_AWBavailable_datatype, to ADC
          signal RbmESP_CDD_Active: start 269, 1 bit, big-endian, base-type=uint8, compu {identical}, implementation-data-type=RbmESP_CDD_Active_datatype, to ADC
          signal RbmESP_CDD_Available: start 268, 1 bit, big-endian, base-type=uint8, compu {identical}, implementation-data-type=RbmESP_CDD_Available_datatype, to ADC
          signal RbmESP_PrefillActive: start 260, 1 bit, big-endian, base-type=uint8, compu {identical}, implementation-data-type=RbmESP_PrefillActive_datatype, to ADC
          signal RbmESP_PrefillAvailable: start 259, 1 bit, big-endian, base-type=uint8, compu {identical}, implementation-data-type=RbmESP_PrefillAvailable_datatype, to ADC
          signal RbmESP_QDCACC: start 279, 2 bit, big-endian, base-type=uint8, compu {identical}, implementation-data-type=RbmESP_QDCACC_datatype, to ADC
          signal RbmEpbFailrLamp_Secondary: start 476, 2 bit, big-endian, base-type=uint8, compu {identical}, implementation-data-type=RbmEpbFailrLamp_Secondary_datatype, to ADC
          signal RbmEpbFctLamp_Secondary: start 410, 2 bit, big-endian, base-type=uint8, compu {identical}, implementation-data-type=RbmEpbFctLamp_Secondary_datatype, to ADC
          signal RbmEpbStsSecondary: start 479, 3 bit, big-endian, base-type=uint8, compu {identical}, implementation-data-type=RbmEpbStsSecondary_datatype, to ADC
          signal RbmEpbTextDispReq_Secondary: start 495, 4 bit, big-endian, base-type=uint8, compu {identical}, implementation-data-type=RbmEpbTextDispReq_Secondary_datatype, to ADC
          signal RbmEspAbsFailr: start 455, 1 bit, big-endian, base-type=uint8, compu {identical}, implementation-data-type=RbmEspAbsFailr_datatype, to ADC
          signal RbmEspVehSpdVld: start 453, 1 bit, big-endian, base-type=uint8, compu {identical}, implementation-data-type=RbmEspVehSpdVld_datatype, to ADC
          signal RbmRbmEspVehSpd: start 452, 13 bit, big-endian, base-type=uint16, compu {texttable; unit km/h}, implementation-data-type=RbmRbmEspVehSpd_datatype, to ADC
          signal RbmWheel_Speed_FL_Data: start 20, 13 bit, big-endian, base-type=uint16, compu {texttable; unit km/h}, implementation-data-type=RbmWheel_Speed_FL_Data_datatype, to ADC
          signal RbmWheel_Speed_FL_Direction: start 22, 2 bit, big-endian, base-type=uint8, compu {identical}, implementation-data-type=RbmWheel_Speed_FL_Direction_datatype, to ADC
          signal RbmWheel_Speed_FL_Pulse: start 215, 8 bit, big-endian, base-type=uint8, compu {texttable}, implementation-data-type=RbmWheel_Speed_FL_Pulse_datatype, to ADC
          signal RbmWheel_Speed_FL_Valid_Data: start 23, 1 bit, big-endian, base-type=uint8, compu {identical}, implementation-data-type=RbmWheel_Speed_FL_Valid_Data_datatype, to ADC
          signal RbmWheel_Speed_FR_Data: start 4, 13 bit, big-endian, base-type=uint16, compu {texttable; unit km/h}, implementation-data-type=RbmWheel_Speed_FR_Data_datatype, to ADC
          signal RbmWheel_Speed_FR_Direction: start 6, 2 bit, big-endian, base-type=uint8, compu {identical}, implementation-data-type=RbmWheel_Speed_FR_Direction_datatype, to ADC
          signal RbmWheel_Speed_FR_Pulse: start 223, 8 bit, big-endian, base-type=uint8, compu {texttable}, implementation-data-type=RbmWheel_Speed_FR_Pulse_datatype, to ADC
          signal RbmWheel_Speed_FR_Valid_Data: start 7, 1 bit, big-endian, base-type=uint8, compu {identical}, implementation-data-type=RbmWheel_Speed_FR_Valid_Data_datatype, to ADC
          signal RbmWheel_Speed_RL_Data: start 84, 13 bit, big-endian, base-type=uint16, compu {texttable; unit km/h}, implementation-data-type=RbmWheel_Speed_RL_Data_datatype, to ADC
          signal RbmWheel_Speed_RL_Direction: start 86, 2 bit, big-endian, base-type=uint8, compu {identical}, implementation-data-type=RbmWheel_Speed_RL_Direction_datatype, to ADC
          signal RbmWheel_Speed_RL_Pulse: start 239, 8 bit, big-endian, base-type=uint8, compu {texttable}, implementation-data-type=RbmWheel_Speed_RL_Pulse_datatype, to ADC
          signal RbmWheel_Speed_RL_Valid_Data: start 87, 1 bit, big-endian, base-type=uint8, compu {identical}, implementation-data-type=RbmWheel_Speed_RL_Valid_Data_datatype, to ADC
          signal RbmWheel_Speed_RR_Data: start 68, 13 bit, big-endian, base-type=uint16, compu {texttable; unit km/h}, implementation-data-type=RbmWheel_Speed_RR_Data_datatype, to ADC
          signal RbmWheel_Speed_RR_Direction: start 70, 2 bit, big-endian, base-type=uint8, compu {identical}, implementation-data-type=RbmWheel_Speed_RR_Direction_datatype, to ADC
          signal RbmWheel_Speed_RR_Pulse: start 231, 8 bit, big-endian, base-type=uint8, compu {texttable}, implementation-data-type=RbmWheel_Speed_RR_Pulse_datatype, to ADC
          signal RbmWheel_Speed_RR_Valid_Data: start 71, 1 bit, big-endian, base-type=uint8, compu {identical}, implementation-data-type=RbmWheel_Speed_RR_Valid_Data_datatype, to ADC
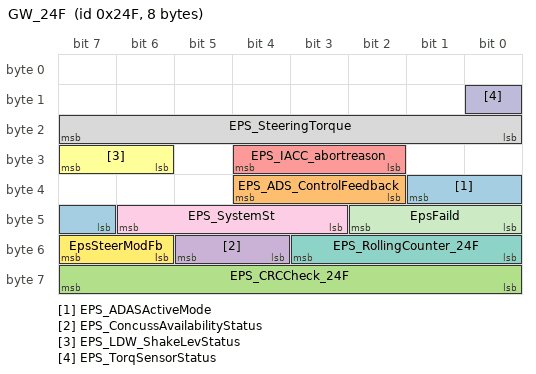
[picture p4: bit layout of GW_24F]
      frame GW_24F: id 0x24F, from GW, to ADC FC_Public, frame-length=8, can-addressing-mode=STANDARD
        pdu GW_24F: length=1
          signal EPS_ADASActiveMode: start 33, 3 bit, big-endian, base-type=uint8, compu {identical}, implementation-data-type=EPS_ADASActiveMode_datatype, to ADC FC_Public
          signal EPS_ADS_ControlFeedback: start 36, 3 bit, big-endian, base-type=uint8, compu {identical}, implementation-data-type=EPS_ADS_ControlFeedback_datatype, to ADC
          signal EPS_CRCCheck_24F: start 63, 8 bit, big-endian, base-type=uint8, compu {texttable}, implementation-data-type=EPS_CRCCheck_24F_datatype, to ADC FC_Public
          signal EPS_ConcussAvailabilityStatus: start 53, 2 bit, big-endian, base-type=uint8, compu {identical}, implementation-data-type=EPS_ConcussAvailabilityStatus_datatype, to ADC FC_Public
          signal EPS_IACC_abortreason: start 28, 3 bit, big-endian, base-type=uint8, compu {identical}, implementation-data-type=EPS_IACC_abortreason_datatype, to ADC FC_Public
          signal EPS_LDW_ShakeLevStatus: start 31, 2 bit, big-endian, base-type=uint8, compu {identical}, implementation-data-type=EPS_LDW_ShakeLevStatus_datatype, to ADC FC_Public
          signal EPS_RollingCounter_24F: start 51, 4 bit, big-endian, base-type=uint8, compu {texttable}, implementation-data-type=EPS_RollingCounter_24F_datatype, to ADC FC_Public
          signal EPS_SteeringTorque: start 23, 8 bit, big-endian, base-type=uint8, compu {texttable; unit Nm}, implementation-data-type=EPS_SteeringTorque_datatype, to ADC FC_Public
          signal EPS_SystemSt: start 46, 4 bit, big-endian, base-type=uint8, compu {identical}, implementation-data-type=EPS_SystemSt_datatype, to ADC FC_Public
          signal EPS_TorqSensorStatus: start 8, 1 bit, big-endian, base-type=uint8, compu {identical}, implementation-data-type=EPS_TorqSensorStatus_datatype, to ADC FC_Public
          signal EpsFaild: start 42, 3 bit, big-endian, base-type=uint8, compu {identical}, implementation-data-type=EpsFaild_datatype, to ADC FC_Public
          signal EpsSteerModFb: start 55, 2 bit, big-endian, base-type=uint8, compu {identical}, implementation-data-type=EpsSteerModFb_datatype, to ADC FC_Public
      frame GW_288: id 0x288, from GW, to ADC FC_Public, frame-length=8, can-addressing-mode=STANDARD
        pdu GW_288: length=1
          signal BcmAutHeadLiSts: start 16, 1 bit, big-endian, base-type=uint8, compu {identical}, implementation-data-type=BcmAutHeadLiSts_datatype, to ADC FC_Public
          signal BcmCrcChk288: start 63, 8 bit, big-endian, base-type=uint8, compu {texttable}, implementation-data-type=BcmCrcChk288_datatype, to ADC FC_Public
          signal BcmCycCntr288: start 51, 4 bit, big-endian, base-type=uint8, compu {texttable}, implementation-data-type=BcmCycCntr288_datatype, to ADC FC_Public
          signal BcmDrvrDoorSts: start 23, 1 bit, big-endian, base-type=uint8, compu {identical}, implementation-data-type=BcmDrvrDoorSts_datatype, to ADC FC_Public
          signal BcmFrntFogLmpSts: start 3, 2 bit, big-endian, base-type=uint8, compu {identical}, implementation-data-type=BcmFrntFogLmpSts_datatype, to ADC FC_Public
          signal BcmFrntWiperSts: start 47, 2 bit, big-endian, base-type=uint8, compu {identical}, implementation-data-type=BcmFrntWiperSts_datatype, to ADC FC_Public
          signal BcmHiBeamSts: start 5, 2 bit, big-endian, base-type=uint8, compu {identical}, implementation-data-type=BcmHiBeamSts_datatype, to ADC FC_Public
          signal BcmHoodSts: start 18, 1 bit, big-endian, base-type=uint8, compu {identical}, implementation-data-type=BcmHoodSts_datatype, to ADC FC_Public
          signal BcmLeReDoorSts: start 21, 1 bit, big-endian, base-type=uint8, compu {identical}, implementation-data-type=BcmLeReDoorSts_datatype, to ADC FC_Public
          signal BcmLiSnsrFlt: start 45, 1 bit, big-endian, base-type=uint8, compu {identical}, implementation-data-type=BcmLiSnsrFlt_datatype, to ADC FC_Public
          signal BcmLoBeamSts: start 7, 2 bit, big-endian, base-type=uint8, compu {identical}, implementation-data-type=BcmLoBeamSts_datatype, to ADC FC_Public
          signal BcmPassDoorSts: start 22, 1 bit, big-endian, base-type=uint8, compu {identical}, implementation-data-type=BcmPassDoorSts_datatype, to ADC FC_Public
          signal BcmReFoglmpSts: start 1, 2 bit, big-endian, base-type=uint8, compu {identical}, implementation-data-type=BcmReFoglmpSts_datatype, to ADC FC_Public
          signal BcmRiReDoorSts: start 20, 1 bit, big-endian, base-type=uint8, compu {identical}, implementation-data-type=BcmRiReDoorSts_datatype, to ADC FC_Public
          signal BcmStsRainSnsr: start 54, 1 bit, big-endian, base-type=uint8, compu {identical}, implementation-data-type=BcmStsRainSnsr_datatype, to ADC FC_Public
          signal BcmTurnIndcrLe: start 15, 2 bit, big-endian, base-type=uint8, compu {identical}, implementation-data-type=BcmTurnIndcrLe_datatype, to ADC FC_Public
          signal BcmTurnIndcrRi: start 13, 2 bit, big-endian, base-type=uint8, compu {identical}, implementation-data-type=BcmTurnIndcrRi_datatype, to ADC FC_Public
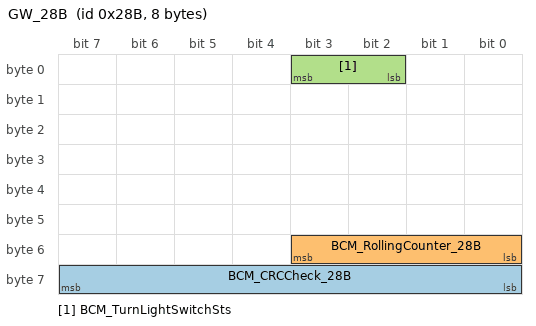
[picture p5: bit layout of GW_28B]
      frame GW_28B: id 0x28B, from GW, to ADC FC_Public, frame-length=8, can-addressing-mode=STANDARD
        pdu GW_28B: length=1
          signal BCM_CRCCheck_28B: start 63, 8 bit, big-endian, base-type=uint8, compu {texttable}, implementation-data-type=BCM_CRCCheck_28B_datatype, to ADC FC_Public
          signal BCM_RollingCounter_28B: start 51, 4 bit, big-endian, base-type=uint8, compu {texttable}, implementation-data-type=BCM_RollingCounter_28B_datatype, to ADC FC_Public
          signal BCM_TurnLightSwitchSts: start 3, 2 bit, big-endian, base-type=uint8, compu {identical}, implementation-data-type=BCM_TurnLightSwitchSts_datatype, to ADC FC_Public
      frame GW_2A4: id 0x2A4, from GW, to ADC FC_Public, frame-length=64, can-addressing-mode=STANDARD
        pdu GW_2A4: length=8
          signal LCDAR_CRCCheck_2AF: start 63, 8 bit, big-endian, base-type=uint8, compu {texttable}, implementation-data-type=LCDAR_CRCCheck_2AF_datatype, to ADC FC_Public
          signal LCDAR_ELK_oAlert: start 25, 2 bit, big-endian, base-type=uint8, compu {identical}, implementation-data-type=LCDAR_ELK_oAlert_datatype, to ADC FC_Public
          signal LCDAR_ELK_oStatus: start 27, 2 bit, big-endian, base-type=uint8, compu {identical}, implementation-data-type=LCDAR_ELK_oStatus_datatype, to ADC FC_Public
          signal LCDAR_Left_ELK_oAlert: start 29, 2 bit, big-endian, base-type=uint8, compu {identical}, implementation-data-type=LCDAR_Left_ELK_oAlert_datatype, to ADC FC_Public
          signal LCDAR_Left_RCTAAlert: start 1, 2 bit, big-endian, base-type=uint8, compu {identical}, implementation-data-type=LCDAR_Left_RCTAAlert_datatype, to ADC FC_Public
          signal LCDAR_RCTBActive: start 19, 1 bit, big-endian, base-type=uint8, compu {identical}, implementation-data-type=LCDAR_RCTBActive_datatype, to ADC FC_Public
          signal LCDAR_RCTBEnable: start 18, 1 bit, big-endian, base-type=uint8, compu {identical}, implementation-data-type=LCDAR_RCTBEnable_datatype, to ADC FC_Public
          signal LCDAR_RCTBTargetDecel: start 39, 16 bit, big-endian, base-type=uint16, compu {texttable; unit m/s2}, implementation-data-type=LCDAR_RCTBTargetDecel_datatype, to ADC FC_Public
          signal LCDAR_RollingCounter_2AF: start 51, 4 bit, big-endian, base-type=uint8, compu {texttable}, implementation-data-type=LCDAR_RollingCounter_2AF_datatype, to ADC FC_Public
      frame GW_2A8: id 0x2A8, from GW, to ADC FC_Public, frame-length=64, can-addressing-mode=STANDARD
        pdu GW_2A8: length=8
          signal TmsAcEnvtlT: start 39, 8 bit, big-endian, base-type=uint8, compu {texttable; unit ��}, implementation-data-type=TmsAcEnvtlT_datatype, to ADC FC_Public
          signal TmsAcEnvtlTVld: start 432, 1 bit, big-endian, base-type=uint8, compu {identical}, implementation-data-type=TmsAcEnvtlTVld_datatype, to ADC FC_Public
          signal TmsActPwr: start 18, 11 bit, big-endian, base-type=uint16, compu {texttable; unit kW}, implementation-data-type=TmsActPwr_datatype, to ADC FC_Public
          signal TmsFrntBlowMod: start 186, 3 bit, big-endian, base-type=uint8, compu {identical}, implementation-data-type=TmsFrntBlowMod_datatype, to ADC FC_Public
      frame GW_2C2: id 0x2C2, from GW, to ADC FC_Public, frame-length=64, can-addressing-mode=STANDARD
        pdu GW_2C2: length=8
          signal IBBrkPedlModSts: start 52, 8 bit, big-endian, base-type=uint8, compu {identical}, implementation-data-type=IBBrkPedlModSts_datatype, to ADC FC_Public
          signal IBBrkPedlModSwtAvl: start 53, 1 bit, big-endian, base-type=uint8, compu {identical}, implementation-data-type=IBBrkPedlModSwtAvl_datatype, to ADC FC_Public
          signal IbBrkPedlStsGb: start 7, 8 bit, big-endian, base-type=uint8, compu {identical; unit %}, implementation-data-type=IbBrkPedlStsGb_datatype, to ADC FC_Public
          signal IbBrkPedlStsGbVld: start 15, 2 bit, big-endian, base-type=uint8, compu {identical}, implementation-data-type=IbBrkPedlStsGbVld_datatype, to ADC FC_Public
          signal IbCrcChk2C2: start 503, 16 bit, big-endian, base-type=uint16, compu {texttable}, implementation-data-type=IbCrcChk2C2_datatype, to ADC FC_Public
          signal IbCycCntr2C2: start 491, 4 bit, big-endian, base-type=uint8, compu {texttable}, implementation-data-type=IbCycCntr2C2_datatype, to ADC FC_Public
      frame GW_2D2: id 0x2D2, from GW, to ADC FC_Public, frame-length=64, can-addressing-mode=STANDARD
        pdu GW_2D2: length=8
          signal CdcCycChk2D2: start 503, 16 bit, big-endian, base-type=uint16, compu {texttable}, implementation-data-type=CdcCycChk2D2_datatype, to ADC FC_Public
          signal CdcCycCntr2D2: start 491, 4 bit, big-endian, base-type=uint8, compu {texttable}, implementation-data-type=CdcCycCntr2D2_datatype, to ADC FC_Public
          signal CdcTotMilg: start 399, 24 bit, big-endian, base-type=uint32, compu {texttable; unit Km}, implementation-data-type=CdcTotMilg_datatype, to ADC FC_Public
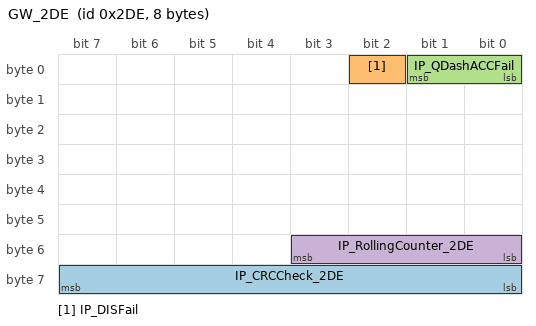
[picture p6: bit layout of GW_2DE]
      frame GW_2DE: id 0x2DE, from GW, to ADC FC_Public, frame-length=8, can-addressing-mode=STANDARD
        pdu GW_2DE: length=1
          signal IP_CRCCheck_2DE: start 63, 8 bit, big-endian, base-type=uint8, compu {texttable}, implementation-data-type=IP_CRCCheck_2DE_datatype, to ADC FC_Public
          signal IP_DISFail: start 2, 1 bit, big-endian, base-type=uint8, compu {identical}, implementation-data-type=IP_DISFail_datatype, to ADC FC_Public
          signal IP_QDashACCFail: start 1, 2 bit, big-endian, base-type=uint8, compu {identical}, implementation-data-type=IP_QDashACCFail_datatype, to ADC FC_Public
          signal IP_RollingCounter_2DE: start 51, 4 bit, big-endian, base-type=uint8, compu {texttable}, implementation-data-type=IP_RollingCounter_2DE_datatype, to ADC FC_Public
      frame GW_3BD: id 0x3BD, from GW, to ADC, frame-length=64, can-addressing-mode=STANDARD
        pdu GW_3BD: length=8
          signal HU_ELKEnable: start 1, 2 bit, big-endian, base-type=uint8, compu {identical}, implementation-data-type=HU_ELKEnable_datatype, to ADC
      frame GW_3C2: id 0x3C2, from GW, to ADC FC_Public, frame-length=64, can-addressing-mode=STANDARD
        pdu GW_3C2: length=8
          signal EpbFailrSts: start 1, 2 bit, big-endian, base-type=uint8, compu {identical}, implementation-data-type=EpbFailrSts_datatype, to ADC FC_Public
          signal EpbSts: start 7, 3 bit, big-endian, base-type=uint8, compu {identical}, implementation-data-type=EpbSts_datatype, to ADC FC_Public
          signal EpbStsPrimary: start 79, 3 bit, big-endian, base-type=uint8, compu {identical}, implementation-data-type=EpbStsPrimary_datatype, to ADC FC_Public
          signal EspCrcChk3C2: start 503, 16 bit, big-endian, base-type=uint16, compu {texttable}, implementation-data-type=EspCrcChk3C2_datatype, to ADC FC_Public
          signal EspCycCntr3C2: start 491, 4 bit, big-endian, base-type=uint8, compu {texttable}, implementation-data-type=EspCycCntr3C2_datatype, to ADC FC_Public
          signal EspEpbReqAvl: start 28, 1 bit, big-endian, base-type=uint8, compu {identical}, implementation-data-type=EspEpbReqAvl_datatype, to ADC FC_Public
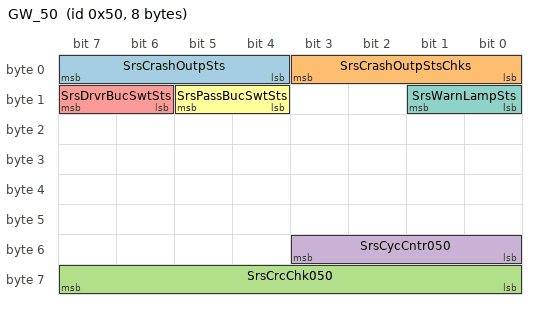
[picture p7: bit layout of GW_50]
      frame GW_50: id 0x50, from GW, to ADC FC_Public, frame-length=8, can-addressing-mode=STANDARD
        pdu GW_50: length=1
          signal SrsCrashOutpSts: start 7, 4 bit, big-endian, base-type=uint8, compu {identical}, implementation-data-type=SrsCrashOutpSts_datatype, to ADC FC_Public
          signal SrsCrashOutpStsChks: start 3, 4 bit, big-endian, base-type=uint8, compu {identical}, implementation-data-type=SrsCrashOutpStsChks_datatype, to ADC FC_Public
          signal SrsCrcChk050: start 63, 8 bit, big-endian, base-type=uint8, compu {texttable}, implementation-data-type=SrsCrcChk050_datatype, to ADC FC_Public
          signal SrsCycCntr050: start 51, 4 bit, big-endian, base-type=uint8, compu {texttable}, implementation-data-type=SrsCycCntr050_datatype, to ADC FC_Public
          signal SrsDrvrBucSwtSts: start 15, 2 bit, big-endian, base-type=uint8, compu {identical}, implementation-data-type=SrsDrvrBucSwtSts_datatype, to ADC FC_Public
          signal SrsPassBucSwtSts: start 13, 2 bit, big-endian, base-type=uint8, compu {identical}, implementation-data-type=SrsPassBucSwtSts_datatype, to ADC FC_Public
          signal SrsWarnLampSts: start 9, 2 bit, big-endian, base-type=uint8, compu {identical}, implementation-data-type=SrsWarnLampSts_datatype, to ADC FC_Public
      frame GW_507: id 0x507, from GW, to ADC, frame-length=64, can-addressing-mode=STANDARD
        pdu GW_507: length=8
          signal HU_AutoBrakeEnable: start 131, 1 bit, big-endian, base-type=uint8, compu {identical}, implementation-data-type=HU_AutoBrakeEnable_datatype, to ADC
          signal HU_FCWSetting: start 165, 3 bit, big-endian, base-type=uint8, compu {identical}, implementation-data-type=HU_FCWSetting_datatype, to ADC
          signal HU_HMAEnable: start 12, 1 bit, big-endian, base-type=uint8, compu {identical}, implementation-data-type=HU_HMAEnable_datatype, to ADC
          signal HU_IACCEnable: start 29, 2 bit, big-endian, base-type=uint8, compu {identical}, implementation-data-type=HU_IACCEnable_datatype, to ADC
          signal HU_LASModeSelection: start 5, 3 bit, big-endian, base-type=uint8, compu {identical}, implementation-data-type=HU_LASModeSelection_datatype, to ADC
          signal HU_LASWarningModeSelection: start 10, 3 bit, big-endian, base-type=uint8, compu {identical}, implementation-data-type=HU_LASWarningModeSelection_datatype, to ADC
          signal HU_VC_CruiseControl: start 138, 3 bit, big-endian, base-type=uint8, compu {identical}, implementation-data-type=HU_VC_CruiseControl_datatype, to ADC
          signal HU_VC_CruiseSetDistance: start 142, 3 bit, big-endian, base-type=uint8, compu {identical}, implementation-data-type=HU_VC_CruiseSetDistance_datatype, to ADC
          signal HU_VC_CruiseSetSpeed: start 151, 8 bit, big-endian, base-type=uint8, compu {identical}, implementation-data-type=HU_VC_CruiseSetSpeed_datatype, to ADC
      frame TBOX_2F7: id 0x2F7, from TBOX, to ADC FC_Public, frame-length=64, can-addressing-mode=STANDARD
        pdu TBOX_2F7: length=8
          signal TboxLocalTiDate: start 20, 5 bit, big-endian, base-type=uint8, compu {texttable; unit day}, implementation-data-type=TboxLocalTiDate_datatype, to ADC FC_Public
          signal TboxLocalTiHr: start 28, 5 bit, big-endian, base-type=uint8, compu {texttable; unit hour}, implementation-data-type=TboxLocalTiHr_datatype, to ADC FC_Public
          signal TboxLocalTiMins: start 37, 6 bit, big-endian, base-type=uint8, compu {texttable; unit minute}, implementation-data-type=TboxLocalTiMins_datatype, to ADC FC_Public
          signal TboxLocalTiMth: start 11, 4 bit, big-endian, base-type=uint8, compu {texttable; unit month}, implementation-data-type=TboxLocalTiMth_datatype, to ADC FC_Public
          signal TboxLocalTiSec: start 45, 6 bit, big-endian, base-type=uint8, compu {texttable; unit second}, implementation-data-type=TboxLocalTiSec_datatype, to ADC FC_Public
          signal TboxLocalTiVld: start 46, 1 bit, big-endian, base-type=uint8, compu {identical}, implementation-data-type=TboxLocalTiVld_datatype, to ADC FC_Public
          signal TboxLocalTiYear: start 7, 8 bit, big-endian, base-type=uint8, compu {texttable; unit year}, implementation-data-type=TboxLocalTiYear_datatype, to ADC FC_Public
      frame VCU_161: id 0x161, from VCU, to ADC, frame-length=64, can-addressing-mode=STANDARD
        pdu VCU_161: length=8
          signal VCUAPARequestEnable: start 4, 2 bit, big-endian, base-type=uint8, compu {identical}, implementation-data-type=VCUAPARequestEnable_datatype, to ADC
          signal VCUAPAdriverInterruption: start 6, 2 bit, big-endian, base-type=uint8, compu {identical}, implementation-data-type=VCUAPAdriverInterruption_datatype, to ADC
          signal VCUAccPedShield: start 7, 1 bit, big-endian, base-type=uint8, compu {identical}, implementation-data-type=VCUAccPedShield_datatype, to ADC
          signal VCUShiftPostionValid: start 2, 1 bit, big-endian, base-type=uint8, compu {identical}, implementation-data-type=VCUShiftPostionValid_datatype, to ADC
          signal VcuAPATorqRequestAvailable: start 19, 1 bit, big-endian, base-type=uint8, compu {identical}, implementation-data-type=VcuAPATorqRequestAvailable_datatype, to ADC
          signal VcuAccrMod: start 1, 3 bit, big-endian, base-type=uint8, compu {identical}, implementation-data-type=VcuAccrMod_datatype, to ADC
          signal VcuAccrPedlPosn: start 14, 10 bit, big-endian, base-type=uint16, compu {texttable; unit %}, implementation-data-type=VcuAccrPedlPosn_datatype, to ADC
          signal VcuAccrPedlPosnVld: start 20, 1 bit, big-endian, base-type=uint8, compu {identical}, implementation-data-type=VcuAccrPedlPosnVld_datatype, to ADC
          signal VcuCalcnAccrPedlPosn: start 18, 10 bit, big-endian, base-type=uint16, compu {texttable; unit %}, implementation-data-type=VcuCalcnAccrPedlPosn_datatype, to ADC
          signal VcuCalcnAccrPedlPosnVld: start 24, 1 bit, big-endian, base-type=uint8, compu {identical}, implementation-data-type=VcuCalcnAccrPedlPosnVld_datatype, to ADC
          signal VcuComFltSts: start 39, 2 bit, big-endian, base-type=uint8, compu {identical}, implementation-data-type=VcuComFltSts_datatype, to ADC
          signal VcuCrcChk161: start 503, 16 bit, big-endian, base-type=uint16, compu {texttable}, implementation-data-type=VcuCrcChk161_datatype, to ADC
          signal VcuCycCntr161: start 491, 4 bit, big-endian, base-type=uint8, compu {texttable}, implementation-data-type=VcuCycCntr161_datatype, to ADC
          signal VcuEnyRecyclMod: start 37, 7 bit, big-endian, base-type=uint8, compu {identical}, implementation-data-type=VcuEnyRecyclMod_datatype, to ADC
          signal VcuGearPosn: start 65, 3 bit, big-endian, base-type=uint8, compu {identical}, implementation-data-type=VcuGearPosn_datatype, to ADC
          signal VcuOvrdModReq: start 78, 1 bit, big-endian, base-type=uint8, compu {identical}, implementation-data-type=VcuOvrdModReq_datatype, to ADC
          signal VcuPtTqLimMax: start 87, 16 bit, big-endian, base-type=uint16, compu {texttable; unit Nm}, implementation-data-type=VcuPtTqLimMax_datatype, to ADC
          signal VcuPtTqLimMaxVld: start 77, 1 bit, big-endian, base-type=uint8, compu {identical}, implementation-data-type=VcuPtTqLimMaxVld_datatype, to ADC
          signal VcuPtTqLimMin: start 103, 16 bit, big-endian, base-type=uint16, compu {texttable; unit Nm}, implementation-data-type=VcuPtTqLimMin_datatype, to ADC
          signal VcuPtTqLimMinVld: start 76, 1 bit, big-endian, base-type=uint8, compu {identical}, implementation-data-type=VcuPtTqLimMinVld_datatype, to ADC
          signal VcuPtTqReal: start 135, 16 bit, big-endian, base-type=uint16, compu {texttable; unit Nm}, implementation-data-type=VcuPtTqReal_datatype, to ADC
          signal VcuPtTqRealVld: start 75, 1 bit, big-endian, base-type=uint8, compu {identical}, implementation-data-type=VcuPtTqRealVld_datatype, to ADC
          signal VcuPtTqReqAvl: start 74, 2 bit, big-endian, base-type=uint8, compu {identical}, implementation-data-type=VcuPtTqReqAvl_datatype, to ADC
          signal VcuRdySts: start 151, 1 bit, big-endian, base-type=uint8, compu {identical}, implementation-data-type=VcuRdySts_datatype, to ADC
          signal VcuShiftLvlPosn: start 119, 4 bit, big-endian, base-type=uint8, compu {identical}, implementation-data-type=VcuShiftLvlPosn_datatype, to ADC
          signal VcuVehGearPosnVld: start 150, 1 bit, big-endian, base-type=uint8, compu {identical}, implementation-data-type=VcuVehGearPosnVld_datatype, to ADC
          signal VcuVehWhlReqTq: start 159, 16 bit, big-endian, base-type=uint16, compu {texttable; unit Nm}, implementation-data-type=VcuVehWhlReqTq_datatype, to ADC
          signal VcuVehWhlReqTqVld: start 149, 1 bit, big-endian, base-type=uint8, compu {identical}, implementation-data-type=VcuVehWhlReqTqVld_datatype, to ADC
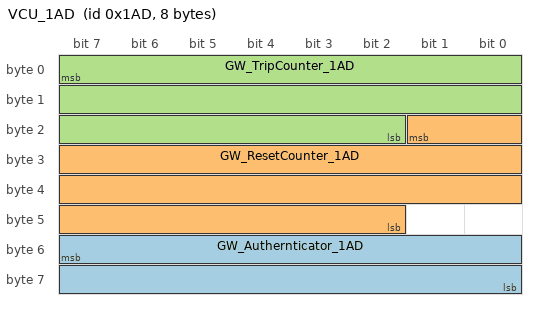
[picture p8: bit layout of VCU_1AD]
      frame VCU_1AD: id 0x1AD, from VCU, to ADC FC_Public, frame-length=8, can-addressing-mode=STANDARD
        pdu VCU_1AD: length=1
          signal GW_Authernticator_1AD: start 55, 16 bit, big-endian, base-type=uint16, compu {texttable}, implementation-data-type=GW_Authernticator_1AD_datatype, to ADC FC_Public
          signal GW_ResetCounter_1AD: start 17, 24 bit, big-endian, base-type=uint32, compu {texttable}, implementation-data-type=GW_ResetCounter_1AD_datatype, to ADC FC_Public
          signal GW_TripCounter_1AD: start 7, 22 bit, big-endian, base-type=uint32, compu {texttable}, implementation-data-type=GW_TripCounter_1AD_datatype, to ADC FC_Public
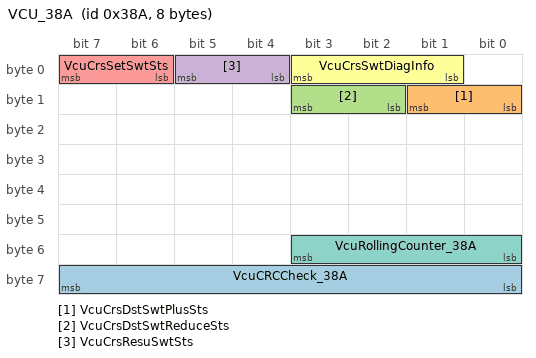
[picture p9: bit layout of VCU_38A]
      frame VCU_38A: id 0x38A, from VCU, to ADC, frame-length=8, can-addressing-mode=STANDARD
        pdu VCU_38A: length=1
          signal VcuCRCCheck_38A: start 63, 8 bit, big-endian, base-type=uint8, compu {texttable}, implementation-data-type=VcuCRCCheck_38A_datatype, to ADC
          signal VcuCrsDstSwtPlusSts: start 9, 2 bit, big-endian, base-type=uint8, compu {identical}, implementation-data-type=VcuCrsDstSwtPlusSts_datatype, to ADC
          signal VcuCrsDstSwtReduceSts: start 11, 2 bit, big-endian, base-type=uint8, compu {identical}, implementation-data-type=VcuCrsDstSwtReduceSts_datatype, to ADC
          signal VcuCrsResuSwtSts: start 5, 2 bit, big-endian, base-type=uint8, compu {identical}, implementation-data-type=VcuCrsResuSwtSts_datatype, to ADC
          signal VcuCrsSetSwtSts: start 7, 2 bit, big-endian, base-type=uint8, compu {identical}, implementation-data-type=VcuCrsSetSwtSts_datatype, to ADC
          signal VcuCrsSwtDiagInfo: start 3, 3 bit, big-endian, base-type=uint8, compu {identical}, implementation-data-type=VcuCrsSwtDiagInfo_datatype, to ADC
          signal VcuRollingCounter_38A: start 51, 4 bit, big-endian, base-type=uint8, compu {texttable}, implementation-data-type=VcuRollingCounter_38A_datatype, to ADC
package /DBCImport/ECUINSTANCES
  5 x ecu instance:
    ADC
      can communication controller ADC
      can communication connector Conn_ADC: comm-controller=ADC
    FC_Public
      can communication controller FC_Public
      can communication connector Conn_FC_Public: comm-controller=FC_Public
    GW
      can communication controller GW
      can communication connector Conn_GW: comm-controller=GW
    TBOX
      can communication controller TBOX
      can communication connector Conn_TBOX: comm-controller=TBOX
    VCU
      can communication controller VCU
      can communication connector Conn_VCU: comm-controller=VCU
package /DBCImport/UNITS
  62 x unit:
    ACC_ACCTargetAcceleration_unit: display-name=m/s2
    ACC_ACCTargetLatRange_unit: display-name=m
    ACC_ACCTargetLngRange_unit: display-name=m
    ACC_ACCTargetRelSpd_unit: display-name=km/h
    ACC_AccTrqReq_unit: display-name=Nm
    ACC_LLaneDistanceFusion_unit: display-name=m
    ACC_LatAngReq_unit: display-name=degree
    ACC_MotorTorqueMaxLimitRequest_unit: display-name=Nm
    ACC_MotorTorqueMinLimitRequest_unit: display-name=Nm
    ACC_RLaneDistanceFusion_unit: display-name=m
    ACC_SetSpeed_unit: display-name=Km/h
    CdcTotMilg_unit: display-name=Km
    EPB_AchievedClampForce_Primary_unit: display-name=KN
    EPB_AchievedClampForce_unit: display-name=KN
    EPS_ActualMotorTorq_unit: display-name=Nm
    EPS_ActualTorsionBarTorq_unit: display-name=Nm
    EPS_Handwheel_Relang_unit: display-name=degree
    EPS_MaxSafetyTorsionBarTorq_unit: display-name=Nm
    EPS_MeasuredTorsionBarTorque_unit: display-name=Nm
    EPS_MinSafetyTorsionBarTorq_unit: display-name=Nm
    EPS_Pinionang_unit: display-name=degree
    EPS_SteeringTorque_unit: display-name=Nm
    EpsSasSteerAg_unit: display-name=degree
    EpsSteerAgRate_unit: display-name=deg/s
    EspReWhlDecTarTq_unit: display-name=Nm
    EspReWhlIncTarTq_unit: display-name=Nm
    EspVehSpd_unit: display-name=km/h
    IBCU_PFSBrakePressure_unit: display-name=bar
    IBCU_PlungerBrakePressure_unit: display-name=bar
    IbBrkPedlStsGb_unit: display-name=%
    LCDAR_RCTBTargetDecel_unit: display-name=m/s2
    MbRgnTarWhl_unit: display-name=Nm
    RbmEPB_AchievedClampForce_Second_unit: display-name=KN
    RbmRbmEspVehSpd_unit: display-name=km/h
    RbmWheel_Speed_FL_Data_unit: display-name=km/h
    RbmWheel_Speed_FR_Data_unit: display-name=km/h
    RbmWheel_Speed_RL_Data_unit: display-name=km/h
    RbmWheel_Speed_RR_Data_unit: display-name=km/h
    TboxLocalTiDate_unit: display-name=day
    TboxLocalTiHr_unit: display-name=hour
    TboxLocalTiMins_unit: display-name=minute
    TboxLocalTiMth_unit: display-name=month
    TboxLocalTiSec_unit: display-name=second
    TboxLocalTiYear_unit: display-name=year
    TmsAcEnvtlT_unit: display-name=��
    TmsActPwr_unit: display-name=kW
    VcuAccrPedlPosn_unit: display-name=%
    VcuCalcnAccrPedlPosn_unit: display-name=%
    VcuPtTqLimMax_unit: display-name=Nm
    VcuPtTqLimMin_unit: display-name=Nm
    VcuPtTqReal_unit: display-name=Nm
    VcuVehWhlReqTq_unit: display-name=Nm
    WheelPressureFrontLeft_Model_unit: display-name=bar
    WheelPressureFrontRight_Model_unit: display-name=bar
    WheelPressureRearLeft_Model_unit: display-name=bar
    WheelPressureRearRight_Model_unit: display-name=bar
    Wheel_SpeedPulseTimeStamp_FL_unit: display-name=ms
    Wheel_SpeedPulseTimeStamp_FR_unit: display-name=ms
    WhlSpdLeFrntData_unit: display-name=km/h
    WhlSpdLeReData_unit: display-name=km/h
    WhlSpdRiFrntData_unit: display-name=km/h
    WhlSpdRiReData_unit: display-name=km/h
